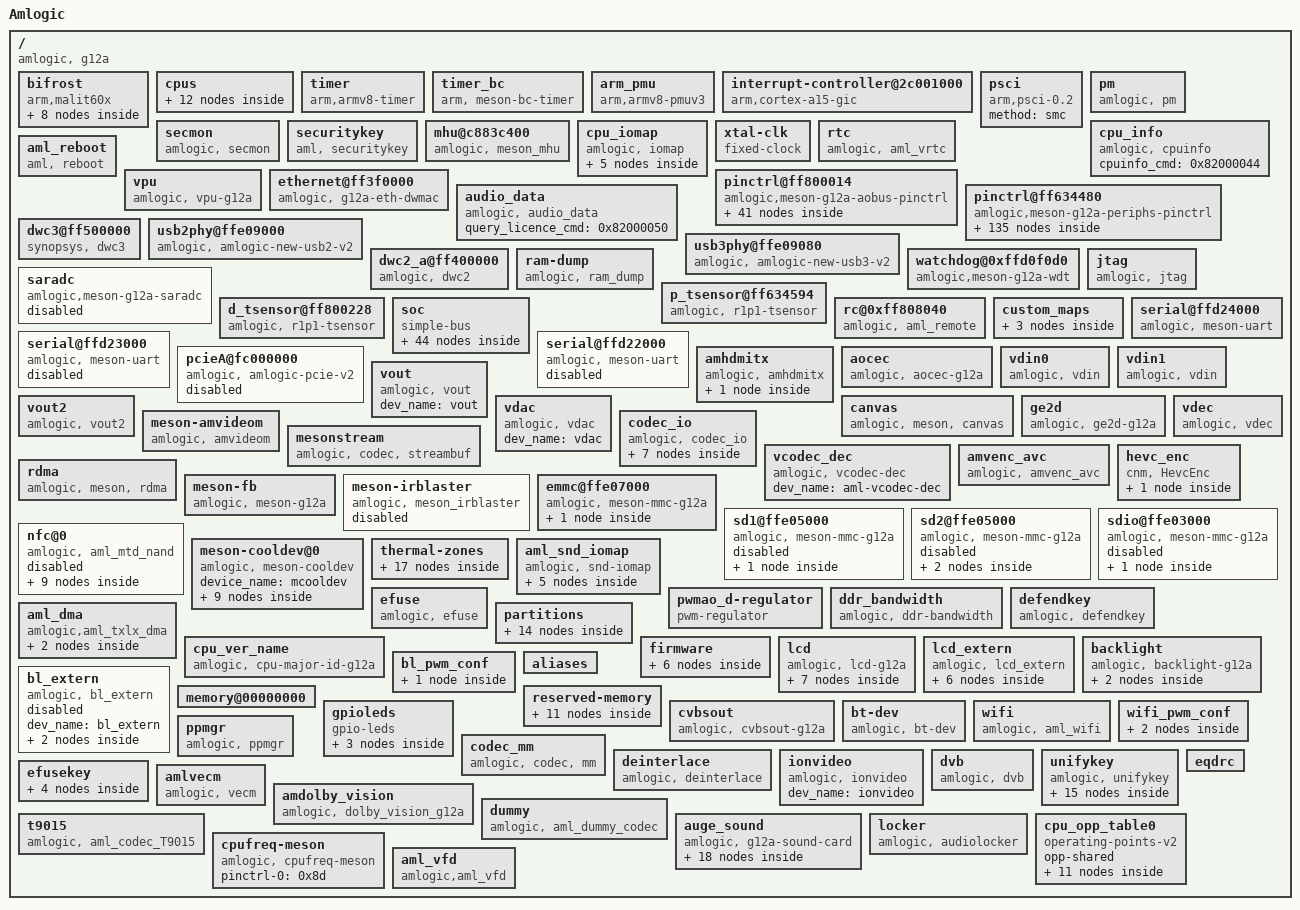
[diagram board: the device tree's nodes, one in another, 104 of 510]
/dts-v1/;

/ {
	model = "Amlogic";
	amlogic-dt-id = "g12a_x2_g10x2g";
	compatible = "amlogic, g12a";
	interrupt-parent = <0x1>;
	#address-cells = <0x2>;
	#size-cells = <0x2>;

	bifrost {
		compatible = "arm,malit60x", "arm,malit6xx", "arm,mali-midgard";
		#cooling-cells = <0x2>;
		reg = <0x0 0xffe40000 0x0 0x4000 0x0 0xffd01000 0x0 0x1000 0x0 0xff800000 0x0 0x1000 0x0 0xff63c000 0x0 0x1000 0x0 0xffd01000 0x0 0x1000>;
		interrupt-parent = <0x1>;
		interrupts = <0x0 0xa0 0x4 0x0 0xa1 0x4 0x0 0xa2 0x4>;
		interrupt-names = "GPU", "MMU", "JOB";
		num_of_pp = <0x2>;
		sc_mpp = <0x1>;
		clocks = <0x2 0x83 0x2 0x7>;
		clock-names = "gpu_mux", "gp0_pll";
		tbl = <0x3 0x4 0x5 0x6 0x7 0x7>;

		clk125_cfg {
			clk_freq = <0x7735940>;
			clk_parent = "fclk_div4";
			clkp_freq = <0x1dcd6500>;
			clk_reg = <0xa03>;
			voltage = <0x47e>;
			keep_count = <0x5>;
			threshold = <0x1e 0x78>;
		};

		dvfs250_cfg {
			clk_freq = <0xee6b280>;
			clk_parent = "fclk_div4";
			clkp_freq = <0x1dcd6500>;
			clk_reg = <0xa01>;
			voltage = <0x47e>;
			keep_count = <0x5>;
			threshold = <0x50 0xaa>;
		};

		dvfs285_cfg {
			clk_freq = <0x1107a76d>;
			clk_parent = "fclk_div7";
			clkp_freq = <0x1107a76d>;
			clk_reg = <0xe00>;
			voltage = <0x47e>;
			keep_count = <0x5>;
			threshold = <0x64 0xbe>;
			linux,phandle = <0x3>;
			phandle = <0x3>;
		};

		dvfs400_cfg {
			clk_freq = <0x17d78400>;
			clk_parent = "fclk_div5";
			clkp_freq = <0x17d78400>;
			clk_reg = <0xc00>;
			voltage = <0x47e>;
			keep_count = <0x5>;
			threshold = <0x98 0xcf>;
			linux,phandle = <0x4>;
			phandle = <0x4>;
		};

		dvfs500_cfg {
			clk_freq = <0x1dcd6500>;
			clk_parent = "fclk_div4";
			clkp_freq = <0x1dcd6500>;
			clk_reg = <0xa00>;
			voltage = <0x47e>;
			keep_count = <0x5>;
			threshold = <0xb4 0xdc>;
			linux,phandle = <0x5>;
			phandle = <0x5>;
		};

		dvfs666_cfg {
			clk_freq = <0x27bc86aa>;
			clk_parent = "fclk_div3";
			clkp_freq = <0x27bc86aa>;
			clk_reg = <0x800>;
			voltage = <0x47e>;
			keep_count = <0x5>;
			threshold = <0xd2 0xec>;
			linux,phandle = <0x6>;
			phandle = <0x6>;
		};

		dvfs800_cfg {
			clk_freq = <0x2faf0800>;
			clk_parent = "fclk_div2p5";
			clkp_freq = <0x2faf0800>;
			clk_reg = <0x600>;
			voltage = <0x47e>;
			keep_count = <0x5>;
			threshold = <0xe6 0xff>;
		};

		dvfs850_cfg {
			clk_freq = <0x326cef80>;
			clk_parent = "gp0_pll";
			clkp_freq = <0x326cef80>;
			clk_reg = <0x200>;
			voltage = <0x47e>;
			keep_count = <0x5>;
			threshold = <0xe6 0xff>;
			linux,phandle = <0x7>;
			phandle = <0x7>;
		};
	};

	cpus {
		#address-cells = <0x2>;
		#size-cells = <0x0>;

		cpu-map {

			cluster0 {

				core0 {
					cpu = <0x8>;
				};

				core1 {
					cpu = <0x9>;
				};

				core2 {
					cpu = <0xa>;
				};

				core3 {
					cpu = <0xb>;
				};
			};
		};

		cpu@0 {
			device_type = "cpu";
			compatible = "arm,cortex-a53", "arm,armv8";
			reg = <0x0 0x0>;
			enable-method = "psci";
			cpu-idle-states = <0xc>;
			clocks = <0x2 0x17 0x2 0x16 0x2 0x0>;
			clock-names = "core_clk", "low_freq_clk_parent", "high_freq_clk_parent";
			operating-points-v2 = <0xd>;
			cpu-supply = <0xe>;
			voltage-tolerance = <0x0>;
			clock-latency = <0xc350>;
			linux,phandle = <0x8>;
			phandle = <0x8>;
		};

		cpu@1 {
			device_type = "cpu";
			compatible = "arm,cortex-a53", "arm,armv8";
			reg = <0x0 0x1>;
			enable-method = "psci";
			cpu-idle-states = <0xc>;
			clocks = <0x2 0x17 0x2 0x16 0x2 0x0>;
			clock-names = "core_clk", "low_freq_clk_parent", "high_freq_clk_parent";
			operating-points-v2 = <0xd>;
			cpu-supply = <0xe>;
			voltage-tolerance = <0x0>;
			clock-latency = <0xc350>;
			linux,phandle = <0x9>;
			phandle = <0x9>;
		};

		cpu@2 {
			device_type = "cpu";
			compatible = "arm,cortex-a53", "arm,armv8";
			reg = <0x0 0x2>;
			enable-method = "psci";
			cpu-idle-states = <0xc>;
			clocks = <0x2 0x17 0x2 0x16 0x2 0x0>;
			clock-names = "core_clk", "low_freq_clk_parent", "high_freq_clk_parent";
			operating-points-v2 = <0xd>;
			cpu-supply = <0xe>;
			voltage-tolerance = <0x0>;
			clock-latency = <0xc350>;
			linux,phandle = <0xa>;
			phandle = <0xa>;
		};

		cpu@3 {
			device_type = "cpu";
			compatible = "arm,cortex-a53", "arm,armv8";
			reg = <0x0 0x3>;
			enable-method = "psci";
			cpu-idle-states = <0xc>;
			clocks = <0x2 0x17 0x2 0x16 0x2 0x0>;
			clock-names = "core_clk", "low_freq_clk_parent", "high_freq_clk_parent";
			operating-points-v2 = <0xd>;
			cpu-supply = <0xe>;
			voltage-tolerance = <0x0>;
			clock-latency = <0xc350>;
			linux,phandle = <0xb>;
			phandle = <0xb>;
		};

		idle-states {
			entry-method = "arm,psci-0.2";

			cpu-sleep-0 {
				compatible = "arm,idle-state";
				arm,psci-suspend-param = <0x10000>;
				local-timer-stop;
				entry-latency-us = <0x1388>;
				exit-latency-us = <0x1388>;
				min-residency-us = <0x3a98>;
				linux,phandle = <0xc>;
				phandle = <0xc>;
			};
		};
	};

	timer {
		compatible = "arm,armv8-timer";
		interrupts = <0x1 0xd 0xff08 0x1 0xe 0xff08 0x1 0xb 0xff08 0x1 0xa 0xff08>;
	};

	timer_bc {
		compatible = "arm, meson-bc-timer";
		reg = <0x0 0xffd0f190 0x0 0x4 0x0 0xffd0f194 0x0 0x4>;
		timer_name = "Meson TimerF";
		clockevent-rating = <0x12c>;
		clockevent-shift = <0x14>;
		clockevent-features = <0x23>;
		interrupts = <0x0 0x3c 0x1>;
		bit_enable = <0x10>;
		bit_mode = <0xc>;
		bit_resolution = <0x0>;
	};

	arm_pmu {
		compatible = "arm,armv8-pmuv3";
		interrupts = <0x0 0x89 0x4>;
		reg = <0x0 0xff634400 0x0 0x1000>;
		sys_cpu_status0_offset = <0xa0>;
		sys_cpu_status0_pmuirq_mask = <0xf>;
		relax_timer_ns = <0x989680>;
		max_wait_cnt = <0x2710>;
	};

	interrupt-controller@2c001000 {
		compatible = "arm,cortex-a15-gic", "arm,cortex-a9-gic";
		#interrupt-cells = <0x3>;
		#address-cells = <0x0>;
		interrupt-controller;
		reg = <0x0 0xffc01000 0x0 0x1000 0x0 0xffc02000 0x0 0x100>;
		interrupts = <0x1 0x9 0xf04>;
		linux,phandle = <0x1>;
		phandle = <0x1>;
	};

	psci {
		compatible = "arm,psci-0.2";
		method = "smc";
	};

	pm {
		compatible = "amlogic, pm";
		status = "okay";
		device_name = "aml_pm";
		reg = <0x0 0xff8000a8 0x0 0x4 0x0 0xff80023c 0x0 0x4>;
	};

	secmon {
		compatible = "amlogic, secmon";
		memory-region = <0xf>;
		in_base_func = <0x82000020>;
		out_base_func = <0x82000021>;
		reserve_mem_size = <0x300000>;
	};

	securitykey {
		compatible = "aml, securitykey";
		storage_query = <0x82000060>;
		storage_read = <0x82000061>;
		storage_write = <0x82000062>;
		storage_tell = <0x82000063>;
		storage_verify = <0x82000064>;
		storage_status = <0x82000065>;
		storage_list = <0x82000067>;
		storage_remove = <0x82000068>;
		storage_in_func = <0x82000023>;
		storage_out_func = <0x82000024>;
		storage_block_func = <0x82000025>;
		storage_size_func = <0x82000027>;
		storage_set_enctype = <0x8200006a>;
		storage_get_enctype = <0x8200006b>;
		storage_version = <0x8200006c>;
	};

	mhu@c883c400 {
		compatible = "amlogic, meson_mhu";
		reg = <0x0 0xff63c400 0x0 0x4c 0x0 0xfffe7000 0x0 0x800>;
		interrupts = <0x0 0xd1 0x1 0x0 0xd2 0x1>;
		#mbox-cells = <0x1>;
		mbox-names = "cpu_to_scp_low", "cpu_to_scp_high";
		mboxes = <0x10 0x0 0x10 0x1>;
		linux,phandle = <0x10>;
		phandle = <0x10>;
	};

	cpu_iomap {
		compatible = "amlogic, iomap";
		#address-cells = <0x2>;
		#size-cells = <0x2>;
		ranges;

		io_cbus_base {
			reg = <0x0 0xffd00000 0x0 0x26000>;
		};

		io_apb_base {
			reg = <0x0 0xffe01000 0x0 0x7f000>;
		};

		io_aobus_base {
			reg = <0x0 0xff800000 0x0 0xb000>;
		};

		io_vapb_base {
			reg = <0x0 0xff900000 0x0 0x50000>;
		};

		io_hiu_base {
			reg = <0x0 0xff63c000 0x0 0x2000>;
		};
	};

	xtal-clk {
		compatible = "fixed-clock";
		clock-frequency = <0x16e3600>;
		clock-output-names = "xtal";
		#clock-cells = <0x0>;
		linux,phandle = <0x14>;
		phandle = <0x14>;
	};

	rtc {
		compatible = "amlogic, aml_vrtc";
		alarm_reg_addr = <0xff8000a8>;
		timer_e_addr = <0xffd0f188>;
		init_date = "2015/01/01";
		status = "okay";
	};

	cpu_info {
		compatible = "amlogic, cpuinfo";
		status = "okay";
		cpuinfo_cmd = <0x82000044>;
	};

	aml_reboot {
		compatible = "aml, reboot";
		sys_reset = <0x84000009>;
		sys_poweroff = <0x84000008>;
	};

	vpu {
		compatible = "amlogic, vpu-g12a";
		dev_name = "vpu";
		status = "okay";
		clocks = <0x2 0x95 0x2 0x4c 0x2 0x87 0x2 0x8b 0x2 0x8c>;
		clock-names = "vapb_clk", "vpu_intr_gate", "vpu_clk0", "vpu_clk1", "vpu_clk";
		clk_level = <0x7>;
	};

	ethernet@ff3f0000 {
		compatible = "amlogic, g12a-eth-dwmac", "snps,dwmac";
		reg = <0x0 0xff3f0000 0x0 0x10000 0x0 0xff634540 0x0 0x8 0x0 0xff64c000 0x0 0xa0>;
		reg-names = "eth_base", "eth_cfg", "eth_pll";
		interrupts = <0x0 0x8 0x1>;
		interrupt-names = "macirq";
		status = "okay";
		clocks = <0x2 0x38>;
		clock-names = "ethclk81";
		pll_val = <0x9c0040a 0x927e0000 0xac5f49e5>;
		analog_val = <0x20200000 0xc000 0x23>;
		pinctrl-names = "external_eth_pins";
		pinctrl-0 = <0x11>;
		mc_val = <0x1621>;
		internal_phy = <0x0>;
	};

	pinctrl@ff800014 {
		compatible = "amlogic,meson-g12a-aobus-pinctrl";
		#address-cells = <0x2>;
		#size-cells = <0x2>;
		ranges;

		ao-bank@ff800014 {
			reg = <0x0 0xff800014 0x0 0x8 0x0 0xff800024 0x0 0x14 0x0 0xff80001c 0x0 0x8>;
			reg-names = "mux", "gpio", "drive-strength";
			gpio-controller;
			#gpio-cells = <0x2>;
			linux,phandle = <0x15>;
			phandle = <0x15>;
		};

		sd_to_ao_uart_clr_pins {
			linux,phandle = <0x40>;
			phandle = <0x40>;

			mux {
				groups = "GPIOAO_0", "GPIOAO_1";
				function = "gpio_aobus";
			};
		};

		sd_to_ao_uart_pins {
			linux,phandle = <0x42>;
			phandle = <0x42>;

			mux {
				groups = "uart_ao_tx_a", "uart_ao_rx_a";
				function = "uart_ao_a";
				bias-pull-up;
				input-enable;
			};
		};

		ao_uart {

			mux {
				groups = "uart_ao_tx_a", "uart_ao_rx_a";
				function = "uart_ao_a";
			};
		};

		ao_b_uart {
			linux,phandle = <0x1a>;
			phandle = <0x1a>;

			mux {
				groups = "uart_ao_tx_b_2", "uart_ao_rx_b_3";
				function = "uart_ao_b";
			};
		};

		ao_i2c_pins1 {

			mux {
				groups = "i2c_ao_sck", "i2c_ao_sda";
				function = "i2c_ao";
				drive-strength = <0x2>;
			};
		};

		ao_i2c_pins2 {

			mux {
				groups = "i2c_ao_sck_e", "i2c_ao_sda_e";
				function = "i2c_ao";
				drive-strength = <0x2>;
			};
		};

		ao_i2c_slave_pins {
			linux,phandle = <0x19>;
			phandle = <0x19>;

			mux {
				groups = "i2c_ao_slave_sck", "i2c_ao_slave_sda";
				function = "i2c_ao_slave";
			};
		};

		pwm_ao_a {

			mux {
				groups = "pwm_ao_a";
				function = "pwm_ao_a";
			};
		};

		pwm_ao_a_hiz {

			mux {
				groups = "pwm_ao_a_hiz";
				function = "pwm_ao_a";
			};
		};

		pwm_ao_b {

			mux {
				groups = "pwm_ao_b";
				function = "pwm_ao_b";
			};
		};

		pwm_ao_c_pins1 {

			mux {
				groups = "pwm_ao_c_4";
				function = "pwm_ao_c";
			};
		};

		pwm_ao_c_pins2 {

			mux {
				groups = "pwm_ao_c_6";
				function = "pwm_ao_c";
			};
		};

		pwm_ao_c_hiz {

			mux {
				groups = "pwm_ao_c_hiz_4";
				function = "pwm_ao_c";
			};
		};

		pwm_ao_d_pins1 {

			mux {
				groups = "pwm_ao_d_5";
				function = "pwm_ao_d";
			};
		};

		pwm_ao_d_pins2 {

			mux {
				groups = "pwm_ao_d_10";
				function = "pwm_ao_d";
			};
		};

		pwm_ao_d_pins3 {
			linux,phandle = <0x8d>;
			phandle = <0x8d>;

			mux {
				groups = "pwm_ao_d_e";
				function = "pwm_ao_d";
			};
		};

		ao_ceca {

			mux {
				groups = "cec_ao_a";
				function = "cec_ao";
			};
		};

		ao_cecb {

			mux {
				groups = "cec_ao_b";
				function = "cec_ao";
			};
		};

		remote_pin {
			linux,phandle = <0x27>;
			phandle = <0x27>;

			mux {
				groups = "remote_input_ao";
				function = "remote_input_ao";
			};
		};

		irblaster_pin {
			linux,phandle = <0x39>;
			phandle = <0x39>;

			mux {
				groups = "remote_out_ao";
				function = "remote_out_ao";
			};
		};
	};

	pinctrl@ff634480 {
		compatible = "amlogic,meson-g12a-periphs-pinctrl";
		#address-cells = <0x2>;
		#size-cells = <0x2>;
		ranges;

		banks@ff6346c0 {
			reg = <0x0 0xff6346c0 0x0 0x40 0x0 0xff6344e8 0x0 0x18 0x0 0xff634520 0x0 0x18 0x0 0xff634440 0x0 0x4c 0x0 0xff634740 0x0 0x1c>;
			reg-names = "mux", "pull", "pull-enable", "gpio", "drive-strength";
			gpio-controller;
			#gpio-cells = <0x2>;
			linux,phandle = <0x16>;
			phandle = <0x16>;
		};

		emmc_clk_cmd_pins {
			linux,phandle = <0x3a>;
			phandle = <0x3a>;

			mux {
				groups = "emmc_clk", "emmc_cmd";
				function = "emmc";
				input-enable;
				bias-pull-up;
			};
		};

		emmc_conf_pull_up {
			linux,phandle = <0x3b>;
			phandle = <0x3b>;

			mux {
				groups = "emmc_nand_d7", "emmc_nand_d6", "emmc_nand_d5", "emmc_nand_d4", "emmc_nand_d3", "emmc_nand_d2", "emmc_nand_d1", "emmc_nand_d0", "emmc_clk", "emmc_cmd";
				function = "emmc";
				input-enable;
				bias-pull-up;
			};
		};

		emmc_conf_pull_done {
			linux,phandle = <0x3c>;
			phandle = <0x3c>;

			mux {
				groups = "emmc_nand_ds";
				function = "emmc";
				input-enable;
				bias-pull-down;
			};
		};

		sd_clk_cmd_pins {
			linux,phandle = <0x3e>;
			phandle = <0x3e>;

			mux {
				groups = "sdcard_cmd_c";
				function = "sdcard";
				input-enable;
				bias-pull-up;
				drive-strength = <0x3>;
			};

			mux1 {
				groups = "sdcard_clk_c";
				function = "sdcard";
				bias-pull-up;
				output-high;
				drive-strength = <0x3>;
			};
		};

		sd_all_pins {
			linux,phandle = <0x3d>;
			phandle = <0x3d>;

			mux {
				groups = "sdcard_d0_c", "sdcard_d1_c", "sdcard_d2_c", "sdcard_d3_c", "sdcard_cmd_c";
				function = "sdcard";
				input-enable;
				bias-pull-up;
				drive-strength = <0x3>;
			};

			mux1 {
				groups = "sdcard_clk_c";
				function = "sdcard";
				bias-pull-up;
				output-high;
				drive-strength = <0x3>;
			};
		};

		sd_1bit_pins {
			linux,phandle = <0x3f>;
			phandle = <0x3f>;

			mux {
				groups = "sdcard_d0_c", "sdcard_cmd_c";
				function = "sdcard";
				input-enable;
				bias-pull-up;
				drive-strength = <0x3>;
			};

			mux1 {
				groups = "sdcard_clk_c";
				function = "sdcard";
				bias-pull-up;
				output-high;
				drive-strength = <0x3>;
			};
		};

		sd_clr_all_pins {
			linux,phandle = <0x46>;
			phandle = <0x46>;

			mux {
				groups = "GPIOC_0", "GPIOC_1", "GPIOC_2", "GPIOC_3", "GPIOC_5";
				function = "gpio_periphs";
				output-high;
				drive-strength = <0x0>;
			};

			mux1 {
				groups = "GPIOC_4";
				function = "gpio_periphs";
				output-low;
				drive-strength = <0x0>;
			};
		};

		sd_clr_noall_pins {
			linux,phandle = <0x45>;
			phandle = <0x45>;

			mux {
				groups = "GPIOC_0", "GPIOC_1", "GPIOC_4", "GPIOC_5";
				function = "gpio_periphs";
				output-high;
				drive-strength = <0x0>;
			};
		};

		ao_to_sd_uart_pins {
			linux,phandle = <0x41>;
			phandle = <0x41>;

			mux {
				groups = "uart_ao_tx_a_c3", "uart_ao_rx_a_c2";
				function = "uart_ao_a_ee";
				bias-pull-up;
				input-enable;
				drive-strength = <0x0>;
			};
		};

		sdio_clk_cmd_pins {
			linux,phandle = <0x4a>;
			phandle = <0x4a>;

			mux {
				groups = "sdio_clk", "sdio_cmd";
				function = "sdio";
				input-enable;
				bias-pull-up;
				drive-strength = <0x3>;
			};
		};

		sdio_all_pins {
			linux,phandle = <0x49>;
			phandle = <0x49>;

			mux {
				groups = "sdio_d0", "sdio_d1", "sdio_d2", "sdio_d3", "sdio_clk", "sdio_cmd";
				function = "sdio";
				input-enable;
				bias-pull-up;
				drive-strength = <0x3>;
			};
		};

		sdio_x_clk_cmd_pins {
			linux,phandle = <0x48>;
			phandle = <0x48>;

			mux {
				groups = "GPIOX_5";
				function = "gpio_periphs";
				input-enable;
				bias-pull-up;
				drive-strength = <0x3>;
			};

			mux1 {
				groups = "GPIOX_4";
				function = "gpio_periphs";
				bias-pull-up;
				output-high;
				drive-strength = <0x3>;
			};
		};

		sdio_x_all_pins {
			linux,phandle = <0x47>;
			phandle = <0x47>;

			mux {
				groups = "GPIOX_0", "GPIOX_1", "GPIOX_2", "GPIOX_3";
				function = "gpio_periphs";
				input-enable;
				bias-pull-up;
				drive-strength = <0x1>;
			};

			mux1 {
				groups = "GPIOX_5";
				function = "gpio_periphs";
				input-enable;
				bias-pull-up;
				drive-strength = <0x3>;
			};

			mux2 {
				groups = "GPIOX_4";
				function = "gpio_periphs";
				bias-pull-up;
				output-high;
				drive-strength = <0x3>;
			};
		};

		sdio_x_en_pins {
			linux,phandle = <0x44>;
			phandle = <0x44>;

			mux {
				groups = "sdio_dummy";
				function = "sdio";
				bias-pull-up;
				output-high;
			};
		};

		sdio_x_clr_pins {
			linux,phandle = <0x43>;
			phandle = <0x43>;

			mux {
				groups = "GPIOV_0";
				function = "gpio_periphs";
				bias-pull-up;
				output-low;
			};

			mux1 {
				groups = "GPIOX_4";
				function = "gpio_periphs";
				output-low;
			};
		};

		all_nand_pins {
			linux,phandle = <0x4b>;
			phandle = <0x4b>;

			mux {
				groups = "emmc_nand_d0", "emmc_nand_d1", "emmc_nand_d2", "emmc_nand_d3", "emmc_nand_d4", "emmc_nand_d5", "emmc_nand_d6", "emmc_nand_d7", "nand_ce0", "nand_ale", "nand_cle", "nand_wen_clk", "nand_ren_wr", "nand_rb0";
				function = "nand";
				input-enable;
			};
		};

		nand_cs {
			linux,phandle = <0x4c>;
			phandle = <0x4c>;

			mux {
				groups = "nand_ce0";
				function = "nand";
			};
		};

		i2c0_pins1 {

			mux {
				groups = "i2c0_sda_c", "i2c0_sck_c";
				function = "i2c0";
				drive-strength = <0x2>;
			};
		};

		i2c0_pins2 {
			linux,phandle = <0x17>;
			phandle = <0x17>;

			mux {
				groups = "i2c0_sda_z0", "i2c0_sck_z1";
				function = "i2c0";
				drive-strength = <0x2>;
			};
		};

		i2c0_pins3 {

			mux {
				groups = "i2c0_sda_z7", "i2c0_sck_z8";
				function = "i2c0";
				drive-strength = <0x2>;
			};
		};

		i2c1_pins1 {

			mux {
				groups = "i2c1_sda_x", "i2c1_sck_x";
				function = "i2c1";
				drive-strength = <0x2>;
			};
		};

		i2c1_pins2 {

			mux {
				groups = "i2c1_sda_h2", "i2c1_sck_h3";
				function = "i2c1";
				drive-strength = <0x2>;
			};
		};

		i2c1_pins3 {

			mux {
				groups = "i2c1_sda_h6", "i2c1_sck_h7";
				function = "i2c1";
				drive-strength = <0x2>;
			};
		};

		i2c2_pins1 {

			mux {
				groups = "i2c2_sda_x", "i2c2_sck_x";
				function = "i2c2";
				drive-strength = <0x2>;
			};
		};

		i2c2_pins2 {

			mux {
				groups = "i2c2_sda_z", "i2c2_sck_z";
				function = "i2c2";
				drive-strength = <0x2>;
			};
		};

		i2c3_pins1 {
			linux,phandle = <0x33>;
			phandle = <0x33>;

			mux {
				groups = "i2c3_sda_h", "i2c3_sck_h";
				function = "i2c3";
				drive-strength = <0x2>;
			};
		};

		i2c3_pins2 {
			linux,phandle = <0x18>;
			phandle = <0x18>;

			mux {
				groups = "i2c3_sda_a", "i2c3_sck_a";
				function = "i2c3";
				drive-strength = <0x2>;
			};
		};

		pwm_a {

			mux {
				groups = "pwm_a";
				function = "pwm_a";
			};
		};

		pwm_b_pins1 {

			mux {
				groups = "pwm_b_x7";
				function = "pwm_b";
			};
		};

		pwm_b_pins2 {

			mux {
				groups = "pwm_b_x19";
				function = "pwm_b";
			};
		};

		pwm_c_pins1 {

			mux {
				groups = "pwm_c_c4";
				function = "pwm_c";
			};
		};

		pwm_c_pins2 {

			mux {
				groups = "pwm_c_x5";
				function = "pwm_c";
			};
		};

		pwm_c_pins3 {

			mux {
				groups = "pwm_c_x8";
				function = "pwm_c";
			};
		};

		pwm_d_pins1 {

			mux {
				groups = "pwm_d_x3";
				function = "pwm_d";
			};
		};

		pwm_d_pins2 {

			mux {
				groups = "pwm_d_x6";
				function = "pwm_d";
			};
		};

		pwm_e {
			linux,phandle = <0x6a>;
			phandle = <0x6a>;

			mux {
				groups = "pwm_e";
				function = "pwm_e";
			};
		};

		pwm_f_pins1 {

			mux {
				groups = "pwm_f_x";
				function = "pwm_f";
			};
		};

		pwm_f_pins2 {
			linux,phandle = <0x67>;
			phandle = <0x67>;

			mux {
				groups = "pwm_f_h";
				function = "pwm_f";
			};
		};

		spicc0_pins_x {

			mux {
				groups = "spi0_mosi_x", "spi0_miso_x", "spi0_clk_x";
				function = "spi0";
				drive-strength = <0x1>;
			};
		};

		spicc0_pins_c {

			mux {
				groups = "spi0_mosi_c", "spi0_miso_c", "spi0_ss0_c", "spi0_clk_c";
				function = "spi0";
				drive-strength = <0x1>;
			};
		};

		spicc1_pins {

			mux {
				groups = "spi1_mosi", "spi1_miso", "spi1_clk";
				function = "spi1";
				drive-strength = <0x1>;
			};
		};

		a_uart {
			linux,phandle = <0x2c>;
			phandle = <0x2c>;

			mux {
				groups = "uart_tx_a", "uart_rx_a", "uart_cts_a", "uart_rts_a";
				function = "uart_a";
			};
		};

		b_uart {
			linux,phandle = <0x2d>;
			phandle = <0x2d>;

			mux {
				groups = "uart_tx_b", "uart_rx_b";
				function = "uart_b";
			};
		};

		c_uart {
			linux,phandle = <0x2e>;
			phandle = <0x2e>;

			mux {
				groups = "uart_tx_c", "uart_rx_c";
				function = "uart_c";
			};
		};

		hdmitx_hpd {
			linux,phandle = <0x30>;
			phandle = <0x30>;

			mux {
				groups = "hdmitx_hpd_in";
				function = "hdmitx";
				bias-disable;
			};
		};

		hdmitx_hpd_gpio {
			linux,phandle = <0x32>;
			phandle = <0x32>;

			mux {
				groups = "GPIOH_1";
				function = "gpio_periphs";
				bias-disable;
			};
		};

		hdmitx_ddc {
			linux,phandle = <0x31>;
			phandle = <0x31>;

			mux {
				groups = "hdmitx_sda", "hdmitx_sck";
				function = "hdmitx";
				bias-disable;
				drive-strength = <0x3>;
			};
		};

		ee_ceca {
			linux,phandle = <0x34>;
			phandle = <0x34>;

			mux {
				groups = "cec_ao_a_ee";
				function = "cec_ao_ee";
			};
		};

		ee_cecb {
			linux,phandle = <0x35>;
			phandle = <0x35>;

			mux {
				groups = "cec_ao_b_ee";
				function = "cec_ao_ee";
			};
		};

		internal_eth_pins {

			mux {
				groups = "eth_link_led", "eth_act_led";
				function = "eth";
			};
		};

		internal_gpio_pins {

			mux {
				groups = "GPIOZ_14", "GPIOZ_15";
				function = "gpio_periphs";
				bias-disable;
				input-enable;
			};
		};

		external_eth_pins {
			linux,phandle = <0x11>;
			phandle = <0x11>;

			mux {
				groups = "eth_mdio", "eth_mdc", "eth_rgmii_rx_clk", "eth_rx_dv", "eth_rxd0", "eth_rxd1", "eth_rxd2_rgmii", "eth_rxd3_rgmii", "eth_rgmii_tx_clk", "eth_txen", "eth_txd0", "eth_txd1", "eth_txd2_rgmii", "eth_txd3_rgmii";
				function = "eth";
				drive-strength = <0x3>;
			};
		};

		tdmout_a {
			linux,phandle = <0x1d>;
			phandle = <0x1d>;

			mux {
				groups = "tdma_sclk", "tdma_fs", "tdma_dout0";
				function = "tdma_out";
			};
		};

		tdmin_a {
			linux,phandle = <0x1e>;
			phandle = <0x1e>;

			mux {
				groups = "tdma_din1";
				function = "tdma_in";
			};
		};

		tdmb_mclk {
			linux,phandle = <0x1f>;
			phandle = <0x1f>;

			mux {
				groups = "mclk0_a";
				function = "mclk0";
				drive-strength = <0x2>;
			};
		};

		tdmout_b {
			linux,phandle = <0x20>;
			phandle = <0x20>;

			mux {
				groups = "tdmb_sclk", "tdmb_fs", "tdmb_dout0";
				function = "tdmb_out";
				drive-strength = <0x2>;
			};
		};

		tdmin_b {
			linux,phandle = <0x21>;
			phandle = <0x21>;

			mux {
				groups = "tdmb_din1";
				function = "tdmb_in";
				drive-strength = <0x2>;
			};
		};

		tdmc_mclk {
			linux,phandle = <0x22>;
			phandle = <0x22>;

			mux {
				groups = "mclk1_a";
				function = "mclk1";
			};
		};

		tdmout_c {
			linux,phandle = <0x23>;
			phandle = <0x23>;

			mux {
				groups = "tdmc_sclk_a", "tdmc_fs_a", "tdmc_dout0_a";
				function = "tdmc_out";
			};
		};

		tdmin_c {
			linux,phandle = <0x24>;
			phandle = <0x24>;

			mux {
				groups = "tdmc_din1_a";
				function = "tdmc_in";
			};
		};

		spdifin {

			mux {
				groups = "spdif_in_h";
				function = "spdif_in";
			};
		};

		spdifout {
			linux,phandle = <0x25>;
			phandle = <0x25>;

			mux {
				groups = "spdif_out_h";
				function = "spdif_out";
			};
		};

		pdmin {
			linux,phandle = <0x26>;
			phandle = <0x26>;

			mux {
				groups = "pdm_din0_a", "pdm_din2_a", "pdm_dclk_a";
				function = "pdm";
			};
		};
	};

	audio_data {
		compatible = "amlogic, audio_data";
		query_licence_cmd = <0x82000050>;
		status = "okay";
	};

	dwc3@ff500000 {
		compatible = "synopsys, dwc3";
		status = "okay";
		reg = <0x0 0xff500000 0x0 0x100000>;
		interrupts = <0x0 0x1e 0x4>;
		usb-phy = <0x12 0x13>;
		cpu-type = "gxl";
		clock-src = "usb3.0";
		clocks = <0x2 0x41>;
		clock-names = "dwc_general";
	};

	usb2phy@ffe09000 {
		compatible = "amlogic, amlogic-new-usb2-v2";
		status = "okay";
		reg = <0x0 0xffe09000 0x0 0x80 0x0 0xffd01008 0x0 0x100 0x0 0xff636000 0x0 0x2000 0x0 0xff63a000 0x0 0x2000>;
		pll-setting-1 = <0x9400414>;
		pll-setting-2 = <0x927e0000>;
		pll-setting-3 = <0xac5f49e5>;
		pll-setting-4 = <0xfe18>;
		pll-setting-5 = <0xfff>;
		pll-setting-6 = <0xc8000>;
		pll-setting-7 = <0xe0004>;
		pll-setting-8 = <0xe000c>;
		portnum = <0x2>;
		linux,phandle = <0x12>;
		phandle = <0x12>;
	};

	usb3phy@ffe09080 {
		compatible = "amlogic, amlogic-new-usb3-v2";
		status = "okay";
		reg = <0x0 0xffe09080 0x0 0x20>;
		phy-reg = <0xff646000>;
		phy-reg-size = <0x2000>;
		usb2-phy-reg = <0xffe09000>;
		usb2-phy-reg-size = <0x80>;
		interrupts = <0x0 0x10 0x4>;
		clocks = <0x2 0x18>;
		clock-names = "pcie_refpll";
		portnum = <0x1>;
		otg = <0x0>;
		linux,phandle = <0x13>;
		phandle = <0x13>;
	};

	dwc2_a@ff400000 {
		compatible = "amlogic, dwc2";
		status = "okay";
		device_name = "dwc2_a";
		reg = <0x0 0xff400000 0x0 0x40000>;
		interrupts = <0x0 0x1f 0x4>;
		pl-periph-id = <0x0>;
		clock-src = "usb0";
		port-id = <0x0>;
		port-type = <0x2>;
		port-speed = <0x0>;
		port-config = <0x0>;
		port-dma = <0x0>;
		port-id-mode = <0x0>;
		usb-fifo = <0x2d8>;
		cpu-type = "v2";
		phy-reg = <0xffe09000>;
		phy-reg-size = <0xa0>;
		phy-interface = <0x0>;
		clocks = <0x2 0x41 0x2 0x49>;
		clock-names = "usb_general", "usb1";
		controller-type = <0x3>;
	};

	watchdog@0xffd0f0d0 {
		compatible = "amlogic,meson-g12a-wdt";
		status = "okay";
		reg = <0x0 0xffd0f0d0 0x0 0x10>;
		clock-names = "xtal";
		clocks = <0x14>;
	};

	ram-dump {
		compatible = "amlogic, ram_dump";
		status = "okay";
	};

	jtag {
		compatible = "amlogic, jtag";
		status = "okay";
		select = "apao";
		jtagao-gpios = <0x15 0x6 0x0 0x15 0x7 0x0 0x15 0x8 0x0 0x15 0x9 0x0>;
		jtagee-gpios = <0x16 0x2a 0x0 0x16 0x2b 0x0 0x16 0x2e 0x0 0x16 0x2f 0x0>;
	};

	saradc {
		compatible = "amlogic,meson-g12a-saradc";
		status = "disabled";
		#io-channel-cells = <0x1>;
		clocks = <0x14 0x2 0xeb>;
		clock-names = "xtal", "saradc_clk";
		interrupts = <0x0 0xc8 0x1>;
		reg = <0x0 0xff809000 0x0 0x48>;
	};

	p_tsensor@ff634594 {
		compatible = "amlogic, r1p1-tsensor";
		device_name = "meson-pthermal";
		status = "okay";
		reg = <0x0 0xff634800 0x0 0x50 0x0 0xff800268 0x0 0x4>;
		cal_type = <0x1>;
		cal_a = <0x144>;
		cal_b = <0x1a8>;
		cal_c = <0xc57>;
		cal_d = <0x24c3>;
		rtemp = <0x1fbd0>;
		interrupts = <0x0 0x23 0x0>;
		clocks = <0x2 0xd2>;
		clock-names = "ts_comp";
		#thermal-sensor-cells = <0x1>;
		linux,phandle = <0x50>;
		phandle = <0x50>;
	};

	d_tsensor@ff800228 {
		compatible = "amlogic, r1p1-tsensor";
		device_name = "meson-dthermal";
		status = "okay";
		reg = <0x0 0xff634c00 0x0 0x50 0x0 0xff800230 0x0 0x4>;
		cal_type = <0x1>;
		cal_a = <0x144>;
		cal_b = <0x1a8>;
		cal_c = <0xc57>;
		cal_d = <0x24c3>;
		rtemp = <0x1fbd0>;
		interrupts = <0x0 0x24 0x0>;
		clocks = <0x2 0xd2>;
		clock-names = "ts_comp";
		#thermal-sensor-cells = <0x1>;
		linux,phandle = <0x56>;
		phandle = <0x56>;
	};

	soc {
		compatible = "simple-bus";
		#address-cells = <0x2>;
		#size-cells = <0x2>;
		ranges;

		cbus@ffd00000 {
			compatible = "simple-bus";
			reg = <0x0 0xffd00000 0x0 0x26000>;
			#address-cells = <0x2>;
			#size-cells = <0x2>;
			ranges = <0x0 0x0 0x0 0xffd00000 0x0 0x26000>;

			interrupt-controller@f080 {
				compatible = "amlogic,meson-gpio-intc", "amlogic,meson-g12a-gpio-intc";
				reg = <0x0 0xf080 0x0 0x10>;
				interrupt-controller;
				#interrupt-cells = <0x2>;
				amlogic,channel-interrupts = <0x40 0x41 0x42 0x43 0x44 0x45 0x46 0x47>;
				status = "okay";
			};

			meson_clk_msr {
				compatible = "amlogic, gxl_measure";
				reg = <0x0 0x18004 0x0 0x4 0x0 0x1800c 0x0 0x4>;
				ringctrl = <0xff6345fc>;
			};

			pwm@1b000 {
				compatible = "amlogic,g12a-ee-pwm";
				reg = <0x0 0x1b000 0x0 0x20>;
				#pwm-cells = <0x3>;
				clocks = <0x14 0x14 0x14 0x14>;
				clock-names = "clkin0", "clkin1", "clkin2", "clkin3";
				status = "disabled";
			};

			pwm@1a000 {
				compatible = "amlogic,g12a-ee-pwm";
				reg = <0x0 0x1a000 0x0 0x20>;
				#pwm-cells = <0x3>;
				clocks = <0x14 0x14 0x14 0x14>;
				clock-names = "clkin0", "clkin1", "clkin2", "clkin3";
				status = "disabled";
			};

			pwm@19000 {
				compatible = "amlogic,g12a-ee-pwm";
				reg = <0x0 0x19000 0x0 0x20>;
				#pwm-cells = <0x3>;
				clocks = <0x14 0x14 0x14 0x14>;
				clock-names = "clkin0", "clkin1", "clkin2", "clkin3";
				status = "okay";
				linux,phandle = <0x69>;
				phandle = <0x69>;
			};

			i2c@1f000 {
				compatible = "amlogic,meson-g12a-i2c";
				status = "okay";
				reg = <0x0 0x1f000 0x0 0x20>;
				interrupts = <0x0 0x15 0x1 0x0 0x5b 0x1>;
				#address-cells = <0x1>;
				#size-cells = <0x0>;
				clocks = <0x2 0x2a>;
				clock-names = "clk_i2c";
				pinctrl-names = "default";
				pinctrl-0 = <0x17>;
				clock-frequency = <0x61a80>;

				gt9xx@5d {
					compatible = "goodix,gt9xx";
					status = "disabled";
					reg = <0x5d>;
					reset-gpio = <0x16 0xa 0x0>;
					irq-gpio = <0x16 0x4 0x0>;
				};

				ftxx@38 {
					compatible = "focaltech,fts";
					status = "disabled";
					reg = <0x38>;
					reset-gpio = <0x16 0xa 0x0>;
					irq-gpio = <0x16 0x4 0x0>;
					x_max = <0x258>;
					y_max = <0x400>;
					max-touch-number = <0xa>;
				};
			};

			i2c@1e000 {
				compatible = "amlogic,meson-g12a-i2c";
				status = "disabled";
				reg = <0x0 0x1e000 0x0 0x20>;
				interrupts = <0x0 0xd6 0x1 0x0 0x5c 0x1>;
				#address-cells = <0x1>;
				#size-cells = <0x0>;
				clocks = <0x2 0x2a>;
				clock-names = "clk_i2c";
			};

			i2c@1d000 {
				compatible = "amlogic,meson-g12a-i2c";
				status = "disabled";
				reg = <0x0 0x1d000 0x0 0x20>;
				interrupts = <0x0 0xd7 0x1 0x0 0x5e 0x1>;
				#address-cells = <0x1>;
				#size-cells = <0x0>;
				clocks = <0x2 0x2a>;
				clock-names = "clk_i2c";
			};

			i2c@1c000 {
				compatible = "amlogic,meson-g12a-i2c";
				status = "okay";
				reg = <0x0 0x1c000 0x0 0x20>;
				interrupts = <0x0 0x27 0x1 0x0 0x5f 0x1>;
				#address-cells = <0x1>;
				#size-cells = <0x0>;
				clocks = <0x2 0x2a>;
				clock-names = "clk_i2c";
				pinctrl-names = "default";
				pinctrl-0 = <0x18>;
				clock-frequency = <0x186a0>;

				ad82584f_62@62 {
					compatible = "ESMT, ad82584f";
					#sound-dai-cells = <0x0>;
					reg = <0x31>;
					status = "disabled";
					reset_pin = <0x16 0x37 0x0>;
				};

				tas5707_36@36 {
					compatible = "ti,tas5707";
					#sound-dai-cells = <0x0>;
					reg = <0x1b>;
					status = "disabled";
					reset_pin = <0x16 0x37 0x0>;
				};

				bl_extern_i2c {
					compatible = "amlogic, bl_extern_i2c";
					status = "disabled";
					reg = <0x2c>;
					dev_name = "lp8556";
				};

				hym8563@51 {
					compatible = "haoyu,hym8563";
					reg = <0x51>;
					interrupts = <0xd 0x2>;
					#clock-cells = <0x0>;
					status = "okay";
				};
			};

			spi@13000 {
				compatible = "amlogic,meson-g12a-spicc";
				reg = <0x0 0x13000 0x0 0x44>;
				interrupts = <0x0 0x51 0x4>;
				clocks = <0x2 0x29 0x2 0xcd>;
				clock-names = "core", "comp";
				#address-cells = <0x1>;
				#size-cells = <0x0>;
				status = "disabled";
			};

			spi@15000 {
				compatible = "amlogic,meson-g12a-spicc";
				reg = <0x0 0x15000 0x0 0x44>;
				interrupts = <0x0 0x5a 0x4>;
				clocks = <0x2 0x2f 0x2 0xd1>;
				clock-names = "core", "comp";
				#address-cells = <0x1>;
				#size-cells = <0x0>;
				status = "disabled";
			};
		};

		aobus@ff800000 {
			compatible = "simple-bus";
			reg = <0x0 0xff800000 0x0 0xb000>;
			#address-cells = <0x2>;
			#size-cells = <0x2>;
			ranges = <0x0 0x0 0x0 0xff800000 0x0 0xb000>;

			cpu_version {
				reg = <0x0 0x220 0x0 0x4>;
			};

			clock-controller@0 {
				compatible = "amlogic,g12a-aoclkc";
				#clock-cells = <0x1>;
				reg = <0x0 0x0 0x0 0x320>;
			};

			pwm@7000 {
				compatible = "amlogic,g12a-ao-pwm";
				reg = <0x0 0x7000 0x0 0x20>;
				#pwm-cells = <0x3>;
				clocks = <0x14 0x14 0x14 0x14>;
				clock-names = "clkin0", "clkin1", "clkin2", "clkin3";
				status = "disabled";
			};

			pwm@2000 {
				compatible = "amlogic,g12a-ao-pwm";
				reg = <0x0 0x2000 0x0 0x20>;
				#pwm-cells = <0x3>;
				clocks = <0x14 0x14 0x14 0x14>;
				clock-names = "clkin0", "clkin1", "clkin2", "clkin3";
				status = "okay";
				linux,phandle = <0x57>;
				phandle = <0x57>;
			};

			i2c@5000 {
				compatible = "amlogic,meson-g12a-i2c";
				status = "disabled";
				reg = <0x0 0x5000 0x0 0x20>;
				interrupts = <0x0 0xc3 0x1 0x0 0xc9 0x1>;
				#address-cells = <0x1>;
				#size-cells = <0x0>;
				clocks = <0x2 0x2a>;
				clock-names = "clk_i2c";
			};

			i2c_slave@6000 {
				compatible = "amlogic, meson-i2c-slave";
				status = "disabled";
				reg = <0x0 0x6000 0x0 0x20>;
				interrupts = <0x0 0xc2 0x1>;
				pinctrl-names = "default";
				pinctrl-0 = <0x19>;
			};

			serial@3000 {
				compatible = "amlogic, meson-uart";
				reg = <0x0 0x3000 0x0 0x18>;
				interrupts = <0x0 0xc1 0x1>;
				status = "okay";
				clocks = <0x14>;
				clock-names = "clk_uart";
				xtal_tick_en = <0x2>;
				fifosize = <0x40>;
				pinctrl-names = "default";
				support-sysrq = <0x0>;
			};

			serial@4000 {
				compatible = "amlogic, meson-uart";
				reg = <0x0 0x4000 0x0 0x18>;
				interrupts = <0x0 0xc5 0x1>;
				status = "disabled";
				clocks = <0x14>;
				clock-names = "clk_uart";
				fifosize = <0x40>;
				pinctrl-names = "default";
				pinctrl-0 = <0x1a>;
			};
		};

		periphs@ff634400 {
			compatible = "simple-bus";
			reg = <0x0 0xff634400 0x0 0x400>;
			#address-cells = <0x2>;
			#size-cells = <0x2>;
			ranges = <0x0 0x0 0x0 0xff634400 0x0 0x400>;
		};

		hiubus@ff63c000 {
			compatible = "simple-bus";
			reg = <0x0 0xff63c000 0x0 0x2000>;
			#address-cells = <0x2>;
			#size-cells = <0x2>;
			ranges = <0x0 0x0 0x0 0xff63c000 0x0 0x2000>;

			clock-controller@0 {
				compatible = "amlogic,g12a-clkc";
				#clock-cells = <0x1>;
				reg = <0x0 0x0 0x0 0x320>;
				linux,phandle = <0x2>;
				phandle = <0x2>;
			};
		};

		ion_dev {
			compatible = "amlogic, ion_dev";
			memory-region = <0x1b>;
		};

		audiobus@0xff642000 {
			compatible = "amlogic, audio-controller", "simple-bus";
			reg = <0x0 0xff642000 0x0 0x2000>;
			#address-cells = <0x2>;
			#size-cells = <0x2>;
			ranges = <0x0 0x0 0x0 0xff642000 0x0 0x2000>;

			audio_clocks {
				compatible = "amlogic, g12a-audio-clocks";
				#clock-cells = <0x1>;
				reg = <0x0 0x0 0x0 0xb0>;
				linux,phandle = <0x1c>;
				phandle = <0x1c>;
			};

			ddr_manager {
				compatible = "amlogic, g12a-audio-ddr-manager";
				interrupts = <0x0 0x94 0x1 0x0 0x95 0x1 0x0 0x96 0x1 0x0 0x98 0x1 0x0 0x99 0x1 0x0 0x9a 0x1>;
				interrupt-names = "toddr_a", "toddr_b", "toddr_c", "frddr_a", "frddr_b", "frddr_c";
			};

			tdma {
				compatible = "amlogic, g12a-snd-tdma";
				#sound-dai-cells = <0x0>;
				dai-tdm-lane-slot-mask-in = <0x0 0x1>;
				dai-tdm-oe-lane-slot-mask-out = <0x1 0x0>;
				dai-tdm-clk-sel = <0x0>;
				clocks = <0x1c 0x17 0x2 0xc>;
				clock-names = "mclk", "clk_srcpll";
				pinctrl-names = "tdm_pins";
				pinctrl-0 = <0x1d 0x1e>;
				linux,phandle = <0x86>;
				phandle = <0x86>;
			};

			tdmb {
				compatible = "amlogic, g12a-snd-tdmb";
				#sound-dai-cells = <0x0>;
				dai-tdm-lane-slot-mask-in = <0x0 0x1 0x0 0x0>;
				dai-tdm-lane-slot-mask-out = <0x1 0x0 0x0 0x0>;
				dai-tdm-clk-sel = <0x1>;
				clocks = <0x1c 0x18 0x2 0xd 0x2 0xc>;
				clock-names = "mclk", "clk_srcpll", "samesource_sysclk";
				pinctrl-names = "tdm_pins";
				pinctrl-0 = <0x1f 0x20 0x21>;
				samesource_sel = <0x3>;
				linux,phandle = <0x88>;
				phandle = <0x88>;
			};

			tdmc {
				compatible = "amlogic, g12a-snd-tdmc";
				#sound-dai-cells = <0x0>;
				dai-tdm-lane-slot-mask-in = <0x0 0x1 0x0 0x0>;
				#dai-tdm-lane-slot-mask-out = <0x1 0x0 0x1 0x1>;
				#dai-tdm-lane-oe-slot-mask-in = <0x0 0x0 0x0 0x0>;
				dai-tdm-lane-oe-slot-mask-out = <0x1 0x0 0x0 0x0>;
				dai-tdm-clk-sel = <0x2>;
				clocks = <0x1c 0x19 0x2 0xe>;
				clock-names = "mclk", "clk_srcpll";
				pinctrl-names = "tdm_pins";
				pinctrl-0 = <0x22 0x23 0x24>;
				linux,phandle = <0x89>;
				phandle = <0x89>;
			};

			i2s2hdmi {
				compatible = "amlogic, g12a-snd-tdmc";
				#sound-dai-cells = <0x0>;
				dai-tdm-lane-slot-mask-out = <0x1 0x1 0x1 0x1>;
				dai-tdm-clk-sel = <0x2>;
				clocks = <0x1c 0x19 0x2 0xe>;
				clock-names = "mclk", "clk_srcpll";
				i2s2hdmi = <0x1>;
				status = "disabled";
			};

			spdif {
				compatible = "amlogic, g12a-snd-spdif-a";
				#sound-dai-cells = <0x0>;
				clocks = <0x2 0xc 0x2 0x4 0x1c 0x10 0x1c 0x11 0x1c 0x1d 0x1c 0x1e>;
				clock-names = "sysclk", "fixed_clk", "gate_spdifin", "gate_spdifout", "clk_spdifin", "clk_spdifout";
				interrupts = <0x0 0x97 0x1>;
				interrupt-names = "irq_spdifin";
				pinctrl-names = "spdif_pins";
				pinctrl-0 = <0x25>;
				status = "okay";
				linux,phandle = <0x8b>;
				phandle = <0x8b>;
			};

			spdif_b {
				compatible = "amlogic, g12a-snd-spdif-b";
				#sound-dai-cells = <0x0>;
				clocks = <0x2 0xc 0x1c 0x15 0x1c 0x21>;
				clock-names = "sysclk", "gate_spdifout", "clk_spdifout";
				status = "okay";
				linux,phandle = <0x8c>;
				phandle = <0x8c>;
			};

			pdm {
				compatible = "amlogic, g12a-snd-pdm";
				#sound-dai-cells = <0x0>;
				clocks = <0x1c 0x1 0x2 0x3 0x2 0xf 0x1c 0x1f 0x1c 0x20>;
				clock-names = "gate", "sysclk_srcpll", "dclk_srcpll", "pdm_dclk", "pdm_sysclk";
				pinctrl-names = "pdm_pins";
				pinctrl-0 = <0x26>;
				filter_mode = <0x1>;
				status = "okay";
				linux,phandle = <0x8a>;
				phandle = <0x8a>;
			};

			loopback {
				compatible = "amlogic, snd-loopback";
				lb_mode = <0x0>;
				datain_src = <0x4>;
				datain_chnum = <0x8>;
				datain_chmask = <0x3f>;
				datalb_src = <0x2>;
				datalb_chnum = <0x8>;
				datalb_chmask = <0x3>;
				status = "okay";
				linux,phandle = <0x83>;
				phandle = <0x83>;
			};

			resample {
				compatible = "amlogic, g12a-resample";
				clocks = <0x2 0xf 0x1c 0x1c 0x1c 0x24>;
				clock-names = "resample_pll", "resample_src", "resample_clk";
				resample_module = <0x4>;
				status = "okay";
			};

			pwrdet {
				compatible = "amlogic, g12a-power-detect";
				interrupts = <0x0 0x9b 0x1>;
				interrupt-names = "pwrdet_irq";
				pwrdet_src = <0x4>;
				hi_th = <0x70000>;
				lo_th = <0x16000>;
				status = "disabled";
			};
		};
	};

	rc@0xff808040 {
		compatible = "amlogic, aml_remote";
		dev_name = "meson-remote";
		reg = <0x0 0xff808040 0x0 0x44 0x0 0xff808000 0x0 0x20>;
		status = "okay";
		protocol = <0x1>;
		led_blink = <0x1>;
		led_blink_frq = <0x64>;
		interrupts = <0x0 0xc4 0x1>;
		pinctrl-names = "default";
		pinctrl-0 = <0x27>;
		map = <0x28>;
		max_frame_time = <0xc8>;
	};

	custom_maps {
		mapnum = <0x3>;
		map0 = <0x29>;
		map1 = <0x2a>;
		map2 = <0x2b>;
		linux,phandle = <0x28>;
		phandle = <0x28>;

		map_0 {
			mapname = "amlogic-remote-1";
			customcode = <0xfb04>;
			release_delay = <0x50>;
			size = <0x32>;
			keymap = <0x47000b 0x130002 0x100003 0x110004 0xf0005 0xc0006 0xd0007 0xb0008 0x80009 0x9000a 0x5c0061 0x51003d 0x50003e 0x40003f 0x4d0040 0x430041 0x170042 0x43 0x10044 0x160057 0x49000e 0x60082 0x140083 0x440067 0x1d006c 0x1c0069 0x48006a 0x53007d 0x450068 0x19006d 0x520077 0x5007a 0x59007b 0x1b0078 0x40079 0x1a0074 0xa000f 0xe0071 0x1f0066 0x1e0084 0x70085 0x120086 0x540087 0x20088 0x4f001e 0x420030 0x5d002e 0x4c0020 0x580089 0x55008c>;
			linux,phandle = <0x29>;
			phandle = <0x29>;
		};

		map_1 {
			mapname = "amlogic-remote-2";
			customcode = <0xfe01>;
			release_delay = <0x50>;
			size = <0x35>;
			keymap = <0x10002 0x20003 0x30004 0x40005 0x50006 0x60007 0x70008 0x80009 0x9000a 0xa000b 0x1f01d2 0x15008b 0x16000f 0xc0192 0xd0193 0xe0073 0xf0072 0x110066 0x1c006a 0x1b0069 0x190067 0x1a006c 0x1d001c 0x170071 0x4900db 0x43009e 0x1201d5 0x1401d6 0x1801d7 0x590166 0x5a00a6 0x100074 0x4200a5 0x4400a3 0x1e00a8 0x4b00d0 0x5800a4 0x460082 0x400083 0x380046 0x5701d0 0x5b01d1 0x54018e 0x4c018f 0x4e0190 0x550191 0x5300ed 0x5200ee 0x3900d4 0x4100d5 0xb00d6 0xd8 0x1300d9>;
			linux,phandle = <0x2a>;
			phandle = <0x2a>;
		};

		map_2 {
			mapname = "amlogic-remote-3";
			customcode = <0xbd02>;
			release_delay = <0x50>;
			size = <0x11>;
			keymap = <0xca0067 0xd2006c 0x990069 0xc1006a 0xce0061 0x450074 0xc50085 0x800071 0xd0000f 0xd6007d 0x950066 0xdd0068 0x8c006d 0x890083 0x9c0082 0x9a0078 0xcd0079>;
			linux,phandle = <0x2b>;
			phandle = <0x2b>;
		};
	};

	serial@ffd24000 {
		compatible = "amlogic, meson-uart";
		reg = <0x0 0xffd24000 0x0 0x18>;
		interrupts = <0x0 0x1a 0x1>;
		status = "okay";
		clocks = <0x14 0x2 0x2e>;
		clock-names = "clk_uart", "clk_gate";
		fifosize = <0x80>;
		pinctrl-names = "default";
		pinctrl-0 = <0x2c>;
	};

	serial@ffd23000 {
		compatible = "amlogic, meson-uart";
		reg = <0x0 0xffd23000 0x0 0x18>;
		interrupts = <0x0 0x4b 0x1>;
		status = "disabled";
		clocks = <0x14 0x2 0x3c>;
		clock-names = "clk_uart", "clk_gate";
		fifosize = <0x40>;
		pinctrl-names = "default";
		pinctrl-0 = <0x2d>;
	};

	serial@ffd22000 {
		compatible = "amlogic, meson-uart";
		reg = <0x0 0xffd22000 0x0 0x18>;
		interrupts = <0x0 0x5d 0x1>;
		status = "disabled";
		clocks = <0x14 0x2 0x3c>;
		clock-names = "clk_uart", "clk_gate";
		fifosize = <0x40>;
		pinctrl-names = "default";
		pinctrl-0 = <0x2e>;
	};

	pcieA@fc000000 {
		compatible = "amlogic, amlogic-pcie-v2", "snps,dw-pcie";
		reg = <0x0 0xfc000000 0x0 0x400000 0x0 0xff648000 0x0 0x2000 0x0 0xfc400000 0x0 0x200000 0x0 0xff646000 0x0 0x2000 0x0 0xffd01080 0x0 0x10>;
		reg-names = "elbi", "cfg", "config", "phy", "reset";
		interrupts = <0x0 0xdd 0x0>;
		#interrupt-cells = <0x1>;
		bus-range = <0x0 0xff>;
		#address-cells = <0x3>;
		#size-cells = <0x2>;
		interrupt-map-mask = <0x0 0x0 0x0 0x0>;
		interrupt-map = <0x0 0x0 0x0 0x0 0x1 0x0 0xdf 0x1>;
		device_type = "pci";
		ranges = <0x81000000 0x0 0x0 0x0 0xfc600000 0x0 0x100000 0x82000000 0x0 0xfc700000 0x0 0xfc700000 0x0 0x1900000>;
		num-lanes = <0x1>;
		pcie-num = <0x1>;
		clocks = <0x2 0x18 0x2 0x3f 0x2 0x42>;
		clock-names = "pcie_refpll", "pcie", "pcie_phy";
		gpio-type = <0x2>;
		pcie-apb-rst-bit = <0xf>;
		pcie-phy-rst-bit = <0xe>;
		pcie-ctrl-a-rst-bit = <0xc>;
		status = "disable";
		reset-gpio = <0x16 0x49 0x0>;
	};

	amhdmitx {
		compatible = "amlogic, amhdmitx";
		dev_name = "amhdmitx";
		status = "okay";
		vend-data = <0x2f>;
		pinctrl-names = "default", "hdmitx_i2c";
		pinctrl-0 = <0x30 0x31>;
		pinctrl-1 = <0x32 0x33>;
		clocks = <0x2 0x55 0x2 0x4e 0x2 0x4f 0x2 0x95 0x2 0x8c>;
		clock-names = "venci_top_gate", "venci_0_gate", "venci_1_gate", "hdmi_vapb_clk", "hdmi_vpu_clk";
		interrupts = <0x0 0x39 0x1>;
		interrupt-names = "hdmitx_hpd";
		ic_type = <0xa>;

		vend_data {
			vendor_name = "Amlogic";
			vendor_id = <0x0>;
			linux,phandle = <0x2f>;
			phandle = <0x2f>;
		};
	};

	aocec {
		compatible = "amlogic, aocec-g12a";
		device_name = "aocec";
		status = "okay";
		vendor_name = "Amlogic";
		vendor_id = <0x0>;
		product_desc = "G12A";
		cec_osd_string = "AML_MBOX";
		cec_version = <0x5>;
		port_num = <0x1>;
		ee_cec;
		arc_port_mask = <0x2>;
		interrupts = <0x0 0xcb 0x1 0x0 0xc7 0x1>;
		interrupt-names = "hdmi_aocecb", "hdmi_aocec";
		pinctrl-names = "default", "hdmitx_aocecb", "cec_pin_sleep";
		pinctrl-0 = <0x34>;
		pinctrl-1 = <0x35>;
		pinctrl-2 = <0x35>;
		reg = <0x0 0xff80023c 0x0 0x4 0x0 0xff800000 0x0 0x400 0x0 0xff634400 0x0 0x26>;
		reg-names = "ao_exit", "ao", "periphs";
	};

	vdin0 {
		compatible = "amlogic, vdin";
		dev_name = "vdin0";
		status = "okay";
		reserve-iomap = "true";
		flag_cma = <0x0>;
		interrupts = <0x0 0x53 0x1>;
		rdma-irq = <0x2>;
		vdin_id = <0x0>;
		memory-region = <0x36>;
		tv_bit_mode = <0x15>;
	};

	vdin1 {
		compatible = "amlogic, vdin";
		dev_name = "vdin1";
		status = "okay";
		reserve-iomap = "true";
		flag_cma = <0x0>;
		interrupts = <0x0 0x55 0x1>;
		rdma-irq = <0x4>;
		vdin_id = <0x1>;
		memory-region = <0x37>;
		tv_bit_mode = <0x1>;
	};

	vout {
		compatible = "amlogic, vout";
		dev_name = "vout";
		status = "okay";
	};

	vout2 {
		compatible = "amlogic, vout2";
		dev_name = "vout";
		status = "okay";
		clocks = <0x2 0xc4 0x2 0xc9>;
		clock-names = "vpu_clkc0", "vpu_clkc";
	};

	vdac {
		compatible = "amlogic, vdac";
		dev_name = "vdac";
		status = "okay";
	};

	canvas {
		compatible = "amlogic, meson, canvas";
		dev_name = "amlogic-canvas";
		status = "okay";
		reg = <0x0 0xff638000 0x0 0x2000>;
	};

	ge2d {
		compatible = "amlogic, ge2d-g12a";
		dev_name = "ge2d";
		status = "okay";
		interrupts = <0x0 0x92 0x1>;
		interrupt-names = "ge2d";
		clocks = <0x2 0x95 0x2 0x3d 0x2 0x96>;
		clock-names = "clk_vapb_0", "clk_ge2d", "clk_ge2d_gate";
		reg = <0x0 0xff940000 0x0 0x10000>;
	};

	meson-amvideom {
		compatible = "amlogic, amvideom";
		dev_name = "amvideom";
		status = "okay";
		interrupts = <0x0 0x3 0x1>;
		interrupt-names = "vsync";
	};

	codec_io {
		compatible = "amlogic, codec_io";
		status = "okay";
		#address-cells = <0x2>;
		#size-cells = <0x2>;
		ranges;

		io_cbus_base {
			reg = <0x0 0xffd00000 0x0 0x100000>;
		};

		io_dos_base {
			reg = <0x0 0xff620000 0x0 0x10000>;
		};

		io_hiubus_base {
			reg = <0x0 0xff63c000 0x0 0x2000>;
		};

		io_aobus_base {
			reg = <0x0 0xff800000 0x0 0x10000>;
		};

		io_vcbus_base {
			reg = <0x0 0xff900000 0x0 0x40000>;
		};

		io_dmc_base {
			reg = <0x0 0xff638000 0x0 0x2000>;
		};

		io_efuse_base {
			reg = <0x0 0xff630000 0x0 0x2000>;
		};
	};

	mesonstream {
		compatible = "amlogic, codec, streambuf";
		dev_name = "mesonstream";
		status = "okay";
		clocks = <0x2 0x40 0x2 0x39 0x2 0x43 0x2 0x22 0x2 0xa5 0x2 0xae 0x2 0xb7 0x2 0xc0>;
		clock-names = "parser_top", "demux", "ahbarb0", "vdec", "clk_vdec_mux", "clk_hcodec_mux", "clk_hevc_mux", "clk_hevcb_mux";
	};

	vdec {
		compatible = "amlogic, vdec";
		dev_name = "vdec.0";
		status = "okay";
		interrupts = <0x0 0x3 0x1 0x0 0x17 0x1 0x0 0x20 0x1 0x0 0x2b 0x1 0x0 0x2c 0x1 0x0 0x2d 0x1>;
		interrupt-names = "vsync", "demux", "parser", "mailbox_0", "mailbox_1", "mailbox_2";
	};

	vcodec_dec {
		compatible = "amlogic, vcodec-dec";
		dev_name = "aml-vcodec-dec";
		status = "okay";
	};

	amvenc_avc {
		compatible = "amlogic, amvenc_avc";
		dev_name = "amvenc_avc";
		status = "okay";
		interrupts = <0x0 0x2d 0x1>;
		interrupt-names = "mailbox_2";
	};

	hevc_enc {
		compatible = "cnm, HevcEnc";
		dev_name = "HevcEnc";
		status = "okay";
		interrupts = <0x0 0xbb 0x1>;
		interrupt-names = "wave420l_irq";
		#address-cells = <0x2>;
		#size-cells = <0x2>;
		ranges;

		io_reg_base {
			reg = <0x0 0xff610000 0x0 0x4000>;
		};
	};

	rdma {
		compatible = "amlogic, meson, rdma";
		dev_name = "amlogic-rdma";
		status = "okay";
		interrupts = <0x0 0x59 0x1>;
		interrupt-names = "rdma";
	};

        meson-fb {
                compatible = "amlogic, meson-g12a";
                memory-region = <&fb_reserved>;
                dev_name = "meson-fb";
                status = "okay";
                interrupts = <0 3 1
                        0 89 1>;
                interrupt-names = "viu-vsync", "rdma";
                mem_size = <0x00800000 0x1800000 0x00100000>;
                /* uboot logo,fb0/fb1 memory size,if afbcd fb0=0x01851000 */
                display_mode_default = "1080p60hz";
                scale_mode = <1>;
                /** 0:VPU free scale 1:OSD free scale 2:OSD super scale */
                display_size_default = <1920 1080 1920 3240 32>;
                /*1920*1080*4*3 = 0x17BB000*/
                mem_alloc = <1>;
                logo_addr = "0x7dc00000";
        };

	meson-irblaster {
		compatible = "amlogic, meson_irblaster";
		dev_name = "meson-irblaster";
		reg = <0x0 0xff80014c 0x0 0x10 0x0 0xff800040 0x0 0x4>;
		pinctrl-names = "default";
		pinctrl-0 = <0x39>;
		status = "disable";
	};

	emmc@ffe07000 {
		status = "okay";
		compatible = "amlogic, meson-mmc-g12a";
		reg = <0x0 0xffe07000 0x0 0x800>;
		interrupts = <0x0 0xbf 0x1>;
		pinctrl-names = "emmc_clk_cmd_pins", "emmc_all_pins";
		pinctrl-0 = <0x3a>;
		pinctrl-1 = <0x3b 0x3c>;
		clocks = <0x2 0x35 0x2 0x72 0x2 0x2 0x2 0x5 0x14>;
		clock-names = "core", "clkin0", "clkin1", "clkin2", "xtal";
		bus-width = <0x8>;
		cap-sd-highspeed;
		cap-mmc-highspeed;
		max-frequency = <0xbebc200>;
		non-removable;
		disable-wp;

		emmc {
			pinname = "emmc";
			ocr_avail = <0x200080>;
			tx_delay = <0x0>;
			co_phase = <0x3>;
			calc_f = <0x1>;
			max_req_size = <0x20000>;
			gpio_dat3 = <0x16 0x1d 0x0>;
			hw_reset = <0x16 0x23 0x0>;
			card_type = <0x1>;
			caps = "MMC_CAP_8_BIT_DATA", "MMC_CAP_MMC_HIGHSPEED", "MMC_CAP_SD_HIGHSPEED", "MMC_CAP_NONREMOVABLE", "MMC_CAP_HW_RESET", "MMC_CAP_ERASE", "MMC_CAP_CMD23";
			caps2 = "MMC_CAP2_HS200";
			f_min = <0x61a80>;
			f_max = <0xbebc200>;
		};
	};

	sd1@ffe05000 {
		status = "disabled";
		compatible = "amlogic, meson-mmc-g12a";
		reg = <0x0 0xffe05000 0x0 0x800>;
		interrupts = <0x0 0xbe 0x1>;
		pinctrl-names = "sd_all_pins", "sd_clk_cmd_pins", "sd_1bit_pins", "sd_clk_cmd_uart_pins", "sd_1bit_uart_pins", "sd_to_ao_uart_pins", "ao_to_sd_uart_pins", "sd_to_ao_jtag_pins", "ao_to_sd_jtag_pins";
		pinctrl-0 = <0x3d>;
		pinctrl-1 = <0x3e>;
		pinctrl-2 = <0x3f>;
		pinctrl-3 = <0x40 0x3e 0x41>;
		pinctrl-4 = <0x40 0x3f 0x41>;
		pinctrl-5 = <0x3d 0x42>;
		pinctrl-6 = <0x40 0x41>;
		pinctrl-7 = <0x3d 0x42>;
		pinctrl-8 = <0x40 0x41>;
		clocks = <0x2 0x34 0x2 0x6e 0x2 0x2 0x2 0x5 0x14>;
		clock-names = "core", "clkin0", "clkin1", "clkin2", "xtal";
		bus-width = <0x4>;
		cap-sd-highspeed;
		cap-mmc-highspeed;
		max-frequency = <0x5f5e100>;
		disable-wp;

		sd {
			pinname = "sd";
			ocr_avail = <0x200080>;
			max_req_size = <0x20000>;
			gpio_dat3 = <0x16 0x2d 0x0>;
			jtag_pin = <0x16 0x2a 0x0>;
			gpio_cd = <0x16 0x30 0x0>;
			card_type = <0x5>;
			caps = "MMC_CAP_4_BIT_DATA", "MMC_CAP_MMC_HIGHSPEED", "MMC_CAP_SD_HIGHSPEED";
			f_min = <0x61a80>;
			f_max = <0x2faf080>;
		};
	};

	sd2@ffe05000 {
		status = "disabled";
		compatible = "amlogic, meson-mmc-g12a";
		reg = <0x0 0xffe05000 0x0 0x800>;
		interrupts = <0x0 0xbe 0x4>;
		pinctrl-names = "sd_all_pins", "sd_clk_cmd_pins", "sd_1bit_pins", "sd_clk_cmd_uart_pins", "sd_1bit_uart_pins", "sd_to_ao_uart_pins", "ao_to_sd_uart_pins", "sd_to_ao_jtag_pins", "ao_to_sd_jtag_pins", "sdio_noclr_all_pins", "sdio_noclr_clk_cmd_pins", "sdio_all_pins", "sdio_clk_cmd_pins";
		pinctrl-0 = <0x43 0x3d>;
		pinctrl-1 = <0x43 0x3e>;
		pinctrl-2 = <0x43 0x3f>;
		pinctrl-3 = <0x43 0x40 0x3e 0x41>;
		pinctrl-4 = <0x43 0x40 0x3f 0x41>;
		pinctrl-5 = <0x43 0x3d 0x42>;
		pinctrl-6 = <0x44 0x40 0x45 0x41>;
		pinctrl-7 = <0x44 0x46 0x42>;
		pinctrl-8 = <0x44 0x40 0x45 0x41>;
		pinctrl-9 = <0x45 0x44 0x47>;
		pinctrl-10 = <0x45 0x44 0x48>;
		pinctrl-11 = <0x46 0x44 0x47>;
		pinctrl-12 = <0x46 0x44 0x48>;
		clocks = <0x2 0x34 0x2 0x6e 0x2 0x2 0x2 0x5 0x14>;
		clock-names = "core", "clkin0", "clkin1", "clkin2", "xtal";
		bus-width = <0x4>;
		cap-sd-highspeed;
		cap-mmc-highspeed;
		max-frequency = <0x5f5e100>;
		disable-wp;

		sd {
			pinname = "sd";
			ocr_avail = <0x200080>;
			max_req_size = <0x20000>;
			gpio_dat3 = <0x16 0x2d 0x0>;
			jtag_pin = <0x16 0x2a 0x0>;
			gpio_cd = <0x16 0x30 0x0>;
			card_type = <0x5>;
			caps = "MMC_CAP_4_BIT_DATA", "MMC_CAP_MMC_HIGHSPEED", "MMC_CAP_SD_HIGHSPEED";
			f_min = <0x61a80>;
			f_max = <0x2faf080>;
		};

		sdio {
			pinname = "sdio";
			ocr_avail = <0x200080>;
			max_req_size = <0x20000>;
			card_type = <0x3>;
			caps = "MMC_CAP_4_BIT_DATA", "MMC_CAP_MMC_HIGHSPEED", "MMC_CAP_SD_HIGHSPEED", "MMC_CAP_NONREMOVABLE", "MMC_CAP_UHS_SDR12", "MMC_CAP_UHS_SDR25", "MMC_CAP_UHS_SDR50", "MMC_CAP_UHS_SDR104", "MMC_PM_KEEP_POWER", "MMC_CAP_SDIO_IRQ";
			f_min = <0x61a80>;
			f_max = <0xbebc200>;
		};
	};

	sdio@ffe03000 {
		status = "disabled";
		compatible = "amlogic, meson-mmc-g12a";
		reg = <0x0 0xffe03000 0x0 0x800>;
		interrupts = <0x0 0xbd 0x4>;
		pinctrl-names = "sdio_all_pins", "sdio_clk_cmd_pins";
		pinctrl-0 = <0x49>;
		pinctrl-1 = <0x4a>;
		clocks = <0x2 0x33 0x2 0x6a 0x2 0x2 0x2 0x5 0x14>;
		clock-names = "core", "clkin0", "clkin1", "clkin2", "xtal";
		bus-width = <0x4>;
		cap-sd-highspeed;
		cap-mmc-highspeed;
		max-frequency = <0x5f5e100>;
		disable-wp;

		sdio {
			pinname = "sdio";
			ocr_avail = <0x200080>;
			max_req_size = <0x400>;
			card_type = <0x3>;
			dmode = "pio";
			caps = "MMC_CAP_4_BIT_DATA", "MMC_CAP_MMC_HIGHSPEED", "MMC_CAP_SD_HIGHSPEED", "MMC_CAP_NONREMOVABLE", "MMC_CAP_UHS_SDR12", "MMC_CAP_UHS_SDR25", "MMC_CAP_UHS_SDR50", "MMC_CAP_UHS_SDR104", "MMC_PM_KEEP_POWER", "MMC_CAP_SDIO_IRQ";
			f_min = <0x61a80>;
			f_max = <0xbebc200>;
		};
	};

	nfc@0 {
		compatible = "amlogic, aml_mtd_nand";
		dev_name = "mtdnand";
		status = "disabled";
		reg = <0x0 0xffe07800 0x0 0x200>;
		interrupts = <0x0 0x22 0x1>;
		pinctrl-names = "nand_rb_mod", "nand_norb_mod", "nand_cs_only";
		pinctrl-0 = <0x4b>;
		pinctrl-1 = <0x4b>;
		pinctrl-2 = <0x4c>;
		clocks = <0x2 0x35 0x2 0x72>;
		clock-names = "core", "clkin";
		device_id = <0x0>;
		bl_mode = <0x1>;
		fip_copies = <0x4>;
		fip_size = <0x200000>;
		nand_clk_ctrl = <0xffe07000>;
		plat-names = "bootloader", "nandnormal";
		plat-num = <0x2>;
		plat-part-0 = <0x4d>;
		plat-part-1 = <0x4e>;

		bootloader {
			enable_pad = "ce0";
			busy_pad = "rb0";
			timming_mode = "mode5";
			bch_mode = "bch8_1k";
			t_rea = <0x14>;
			t_rhoh = <0xf>;
			chip_num = <0x1>;
			part_num = <0x0>;
			rb_detect = <0x1>;
			linux,phandle = <0x4d>;
			phandle = <0x4d>;
		};

		nandnormal {
			enable_pad = "ce0";
			busy_pad = "rb0";
			timming_mode = "mode5";
			bch_mode = "bch8_1k";
			plane_mode = "twoplane";
			t_rea = <0x14>;
			t_rhoh = <0xf>;
			chip_num = <0x2>;
			part_num = <0x3>;
			partition = <0x4f>;
			rb_detect = <0x1>;
			linux,phandle = <0x4e>;
			phandle = <0x4e>;
		};

		nand_partition {
			linux,phandle = <0x4f>;
			phandle = <0x4f>;

			tpl {
				offset = <0x0 0x0>;
				size = <0x0 0x0>;
			};

			logo {
				offset = <0x0 0x0>;
				size = <0x0 0x200000>;
			};

			recovery {
				offset = <0x0 0x0>;
				size = <0x0 0x1000000>;
			};

			boot {
				offset = <0x0 0x0>;
				size = <0x0 0x1000000>;
			};

			system {
				offset = <0x0 0x0>;
				size = <0x0 0x4000000>;
			};

			data {
				offset = <0xffffffff 0xffffffff>;
				size = <0x0 0x0>;
			};
		};
	};

	meson-cooldev@0 {
		status = "okay";
		compatible = "amlogic, meson-cooldev";
		device_name = "mcooldev";

		cooling_devices {

			cpufreq_cool_cluster0 {
				min_state = <0xf4240>;
				dyn_coeff = <0x73>;
				cluster_id = <0x0>;
				node_name = "cpufreq_cool0";
				device_type = "cpufreq";
			};

			cpucore_cool_cluster0 {
				min_state = <0x1>;
				dyn_coeff = <0x0>;
				cluster_id = <0x0>;
				node_name = "cpucore_cool0";
				device_type = "cpucore";
			};

			gpufreq_cool {
				min_state = <0x190>;
				dyn_coeff = <0x166>;
				gpu_pp = <0x2>;
				cluster_id = <0x0>;
				node_name = "gpufreq_cool0";
				device_type = "gpufreq";
			};

			gpucore_cool {
				min_state = <0x1>;
				dyn_coeff = <0x0>;
				cluster_id = <0x0>;
				node_name = "gpucore_cool0";
				device_type = "gpucore";
			};
		};

		cpufreq_cool0 {
			#cooling-cells = <0x2>;
			linux,phandle = <0x52>;
			phandle = <0x52>;
		};

		cpucore_cool0 {
			#cooling-cells = <0x2>;
			linux,phandle = <0x53>;
			phandle = <0x53>;
		};

		gpufreq_cool0 {
			#cooling-cells = <0x2>;
			linux,phandle = <0x54>;
			phandle = <0x54>;
		};

		gpucore_cool0 {
			#cooling-cells = <0x2>;
			linux,phandle = <0x55>;
			phandle = <0x55>;
		};
	};

	thermal-zones {

		soc_thermal {
			polling-delay = <0x3e8>;
			polling-delay-passive = <0x64>;
			sustainable-power = <0x5b4>;
			thermal-sensors = <0x50 0x0>;

			trips {

				trip-point@0 {
					temperature = <0xea60>;
					hysteresis = <0x1388>;
					type = "passive";
				};

				trip-point@1 {
					temperature = <0x124f8>;
					hysteresis = <0x1388>;
					type = "passive";
					linux,phandle = <0x51>;
					phandle = <0x51>;
				};

				trip-point@2 {
					temperature = <0x14c08>;
					hysteresis = <0x1388>;
					type = "hot";
				};

				trip-point@3 {
					temperature = <0x249f0>;
					hysteresis = <0x3e8>;
					type = "critical";
				};
			};

			cooling-maps {

				cpufreq_cooling_map {
					trip = <0x51>;
					cooling-device = <0x52 0x0 0x4>;
					contribution = <0x400>;
				};

				cpucore_cooling_map {
					trip = <0x51>;
					cooling-device = <0x53 0x0 0x3>;
					contribution = <0x400>;
				};

				gpufreq_cooling_map {
					trip = <0x51>;
					cooling-device = <0x54 0x0 0x4>;
					contribution = <0x400>;
				};

				gpucore_cooling_map {
					trip = <0x51>;
					cooling-device = <0x55 0x0 0x2>;
					contribution = <0x400>;
				};
			};
		};

		ddr_thermal {
			polling-delay = <0x3e8>;
			polling-delay-passive = <0x64>;
			sustainable-power = <0x866>;
			thermal-sensors = <0x56 0x1>;

			trips {

				trip-point@0 {
					temperature = <0xea60>;
					hysteresis = <0x1388>;
					type = "passive";
				};

				trip-point@1 {
					temperature = <0x124f8>;
					hysteresis = <0x1388>;
					type = "passive";
				};

				trip-point@2 {
					temperature = <0x14c08>;
					hysteresis = <0x1388>;
					type = "hot";
				};

				trip-point@3 {
					temperature = <0x249f0>;
					hysteresis = <0x3e8>;
					type = "critical";
				};
			};
		};
	};

	aml_snd_iomap {
		compatible = "amlogic, snd-iomap";
		status = "okay";
		#address-cells = <0x2>;
		#size-cells = <0x2>;
		ranges;

		pdm_bus {
			reg = <0x0 0xff640000 0x0 0x2000>;
		};

		audiobus_base {
			reg = <0x0 0xff642000 0x0 0x2000>;
		};

		audiolocker_base {
			reg = <0x0 0xff64a000 0x0 0x2000>;
		};

		eqdrc_base {
			reg = <0x0 0xff642800 0x0 0x1800>;
		};

		reset_base {
			reg = <0x0 0xffd01000 0x0 0x1000>;
		};
	};

	pwmao_d-regulator {
		compatible = "pwm-regulator";
		pwms = <0x57 0x1 0x4e2 0x0>;
		regulator-name = "vddcpu0";
		regulator-min-microvolt = <0xb0068>;
		regulator-max-microvolt = <0xf9830>;
		regulator-always-on;
		max-duty-cycle = <0x4e2>;
		voltage-table = <0xf9830 0x0 0xf6d38 0x3 0xf4628 0x6 0xf1f18 0xa 0xef808 0xd 0xed0f8 0x10 0xea9e8 0x14 0xe82d8 0x17 0xe5bc8 0x1a 0xe34b8 0x1e 0xe0da8 0x21 0xde698 0x24 0xdbf88 0x28 0xd9878 0x2b 0xd7168 0x2e 0xd4a58 0x32 0xd2348 0x35 0xcfc38 0x38 0xcd528 0x3c 0xcae18 0x3f 0xc8708 0x43 0xc5ff8 0x46 0xc38e8 0x49 0xc11d8 0x4c 0xbeac8 0x50 0xbc3b8 0x53 0xb9ca8 0x56 0xb7598 0x5a 0xb4e88 0x5d 0xb2778 0x60 0xb0068 0x64>;
		status = "okay";
		linux,phandle = <0xe>;
		phandle = <0xe>;
	};

	ddr_bandwidth {
		compatible = "amlogic, ddr-bandwidth";
		status = "okay";
		reg = <0x0 0xff638000 0x0 0x100 0x0 0xff638c00 0x0 0x100>;
		interrupts = <0x0 0x34 0x1>;
		interrupt-names = "ddr_bandwidth";
	};

	defendkey {
		compatible = "amlogic, defendkey";
		reg = <0x0 0xff630218 0x0 0x4>;
		mem_size = <0x0 0x1000>;
		status = "okay";
	};

	aml_dma {
		compatible = "amlogic,aml_txlx_dma";
		reg = <0x0 0xff63e000 0x0 0x48>;
		interrupts = <0x0 0xb4 0x1>;

		aml_aes {
			compatible = "amlogic,aes_g12a_dma";
			dev_name = "aml_aes_dma";
			status = "okay";
		};

		aml_sha {
			compatible = "amlogic,sha_dma";
			dev_name = "aml_sha_dma";
			status = "okay";
		};
	};

	efuse {
		compatible = "amlogic, efuse";
		read_cmd = <0x82000030>;
		write_cmd = <0x82000031>;
		get_max_cmd = <0x82000033>;
		key = <0x58>;
		clocks = <0x2 0x61>;
		clock-names = "efuse_clk";
		status = "okay";
	};

	cpu_ver_name {
		compatible = "amlogic, cpu-major-id-g12a";
	};

	partitions {
		parts = <0xe>;
		part-0 = <0x59>;
		part-1 = <0x5a>;
		part-2 = <0x5b>;
		part-3 = <0x5c>;
		part-4 = <0x5d>;
		part-5 = <0x5e>;
		part-6 = <0x5f>;
		part-7 = <0x60>;
		part-8 = <0x61>;
		part-9 = <0x62>;
		part-10 = <0x63>;
		part-11 = <0x64>;
		part-12 = <0x65>;
		part-13 = <0x66>;

		logo {
			pname = "logo";
			size = <0x0 0x800000>;
			mask = <0x1>;
			linux,phandle = <0x59>;
			phandle = <0x59>;
		};

		recovery {
			pname = "recovery";
			size = <0x0 0x1800000>;
			mask = <0x1>;
			linux,phandle = <0x5a>;
			phandle = <0x5a>;
		};

		misc {
			pname = "misc";
			size = <0x0 0x800000>;
			mask = <0x1>;
			linux,phandle = <0x5b>;
			phandle = <0x5b>;
		};

		dto {
			pname = "dto";
			size = <0x0 0x800000>;
			mask = <0x1>;
			linux,phandle = <0x5c>;
			phandle = <0x5c>;
		};

		cri_data {
			pname = "cri_data";
			size = <0x0 0x800000>;
			mask = <0x2>;
			linux,phandle = <0x5d>;
			phandle = <0x5d>;
		};

		rsv {
			pname = "rsv";
			size = <0x0 0x1000000>;
			mask = <0x1>;
			linux,phandle = <0x60>;
			phandle = <0x60>;
		};

		param {
			pname = "param";
			size = <0x0 0x1000000>;
			mask = <0x2>;
			linux,phandle = <0x5e>;
			phandle = <0x5e>;
		};

		boot {
			pname = "boot";
			size = <0x0 0x1000000>;
			mask = <0x1>;
			linux,phandle = <0x5f>;
			phandle = <0x5f>;
		};

		tee {
			pname = "tee";
			size = <0x0 0x2000000>;
			mask = <0x1>;
			linux,phandle = <0x61>;
			phandle = <0x61>;
		};

		vendor {
			pname = "vendor";
			size = <0x0 0x10000000>;
			mask = <0x1>;
			linux,phandle = <0x62>;
			phandle = <0x62>;
		};

		odm {
			pname = "odm";
			size = <0x0 0x10000000>;
			mask = <0x1>;
			linux,phandle = <0x63>;
			phandle = <0x63>;
		};

		system {
			pname = "system";
			size = <0x0 0x74000000>;
			mask = <0x1>;
			linux,phandle = <0x64>;
			phandle = <0x64>;
		};

		cache {
			pname = "cache";
			size = <0x0 0x46000000>;
			mask = <0x2>;
			linux,phandle = <0x65>;
			phandle = <0x65>;
		};

		data {
			pname = "data";
			size = <0xffffffff 0xffffffff>;
			mask = <0x4>;
			linux,phandle = <0x66>;
			phandle = <0x66>;
		};
	};

	firmware {

		android {
			compatible = "android,firmware";

			vbmeta {
				compatible = "android,vbmeta";
				parts = "boot,system,vendor";
				by_name_prefix = "/dev/block";
			};

			fstab {
				compatible = "android,fstab";

				system {
					compatible = "android,system";
					dev = "/dev/block/system";
					type = "ext4";
					mnt_flags = "ro,barrier=1,inode_readahead_blks=8";
					fsmgr_flags = "wait";
				};

				vendor {
					compatible = "android,vendor";
					dev = "/dev/block/vendor";
					type = "ext4";
					mnt_flags = "ro,barrier=1,inode_readahead_blks=8";
					fsmgr_flags = "wait";
				};

				odm {
					compatible = "android,odm";
					dev = "/dev/block/odm";
					type = "ext4";
					mnt_flags = "ro,barrier=1,inode_readahead_blks=8";
					fsmgr_flags = "wait";
				};
			};
		};
	};

	lcd {
		compatible = "amlogic, lcd-g12a";
		dev_name = "lcd";
		mode = "tablet";
		status = "okay";
		key_valid = <0x0>;
		clocks = <0x2 0x24 0x2 0x31 0x2 0x9a 0x2 0x5d 0x2 0x5f>;
		clock-names = "dsi_host_gate", "dsi_phy_gate", "dsi_meas", "encl_top_gate", "encl_int_gate";
		reg = <0x0 0xffd07000 0x0 0x400 0x0 0xff644000 0x0 0x2000>;
		pinctrl_version = <0x2>;
		lcd_cpu-gpios = <0x16 0xa 0x0 0x16 0x9 0x0>;
		lcd_cpu_gpio_names = "GPIOZ_9", "GPIOZ_8";

		lcd_0 {
			model_name = "B080XAN01";
			interface = "mipi";
			basic_setting = <0x300 0x400 0x3b4 0x474 0x8 0x77 0x9f>;
			lcd_timing = <0x40 0x38 0x0 0x32 0x1e 0x0>;
			clk_attr = <0x0 0x0 0x1 0x3dd6dc0>;
			mipi_attr = <0x4 0x226 0x0 0x1 0x0 0x2 0x1 0x0>;
			dsi_init_on = <0x5 0x1 0x11 0xff 0x14 0x5 0x1 0x29 0xff 0x14 0xff 0xff>;
			dsi_init_off = <0x5 0x1 0x28 0xff 0xa 0x5 0x1 0x10 0xff 0xa 0xff 0xff>;
			extern_init = <0xff>;
			power_on_step = <0x0 0x1 0x0 0x64 0x0 0x0 0x0 0xa 0x0 0x0 0x1 0x14 0x2 0x0 0x0 0x0 0xff 0x0 0x0 0x0>;
			power_off_step = <0x2 0x0 0x0 0x32 0x0 0x0 0x0 0xa 0x0 0x1 0x1 0x64 0xff 0x0 0x0 0x0>;
			backlight_index = <0x0>;
		};

		lcd_1 {
			model_name = "TV070WSM";
			interface = "mipi";
			basic_setting = <0x258 0x400 0x2bc 0x41d 0x8 0x5f 0xa3>;
			lcd_timing = <0x18 0x24 0x0 0x2 0x8 0x0>;
			clk_attr = <0x0 0x0 0x1 0x2a33390>;
			mipi_attr = <0x4 0x168 0x0 0x1 0x0 0x2 0x0 0x0>;
			dsi_init_on = <0xff 0xa 0xf0 0x3 0x0 0x1 0x1e 0xf0 0x3 0x0 0x0 0xa 0xf0 0x3 0x0 0x1 0x1e 0xfc 0x2 0x4 0x3 0xff 0xff>;
			dsi_init_off = <0xff 0xff>;
			extern_init = <0x1>;
			power_on_step = <0x0 0x1 0x0 0xc8 0x2 0x0 0x0 0x0 0xff 0x0 0x0 0x0>;
			power_off_step = <0x2 0x0 0x0 0x0 0x0 0x0 0x0 0x14 0x0 0x1 0x1 0x64 0xff 0x0 0x0 0x0>;
			backlight_index = <0x0>;
		};

		lcd_2 {
			model_name = "P070ACB";
			interface = "mipi";
			basic_setting = <0x258 0x400 0x2a8 0x4aa 0x8 0x3 0x5>;
			lcd_timing = <0x18 0x24 0x0 0xa 0x50 0x0>;
			clk_attr = <0x0 0x0 0x1 0x2e755c0>;
			mipi_attr = <0x4 0x190 0x0 0x1 0x0 0x2 0x0 0x0>;
			dsi_init_on = <0xff 0xa 0xf0 0x3 0x0 0x1 0x1e 0xf0 0x3 0x0 0x0 0xa 0xf0 0x3 0x0 0x1 0x1e 0xfc 0x2 0x4 0x3 0xff 0xff>;
			dsi_init_off = <0xff 0xff>;
			extern_init = <0x2>;
			power_on_step = <0x0 0x1 0x0 0xc8 0x2 0x0 0x0 0x0 0xff 0x0 0x0 0x0>;
			power_off_step = <0x2 0x0 0x0 0x0 0x0 0x0 0x0 0x14 0x0 0x1 0x1 0x64 0xff 0x0 0x0 0x0>;
			backlight_index = <0x0>;
		};

		lcd_3 {
			model_name = "TL050FHV02CT";
			interface = "mipi";
			basic_setting = <0x438 0x780 0x465 0x834 0x8 0x41 0x77>;
			lcd_timing = <0x5 0x1e 0x0 0x2c 0x6c 0x0>;
			clk_attr = <0x0 0x0 0x1 0x70a71c8>;
			mipi_attr = <0x4 0x3c0 0x0 0x1 0x0 0x2 0x1 0x0>;
			dsi_init_on = <0xff 0xff>;
			dsi_init_off = <0xff 0xff>;
			extern_init = <0x3>;
			power_on_step = <0x0 0x1 0x0 0xc8 0x0 0x0 0x1 0x14 0x0 0x0 0x0 0xa 0x0 0x0 0x1 0x14 0x2 0x0 0x0 0x0 0xff 0x0 0x0 0x0>;
			power_off_step = <0x2 0x0 0x0 0x0 0x0 0x0 0x0 0x14 0x0 0x1 0x1 0x64 0xff 0x0 0x0 0x0>;
			backlight_index = <0x0>;
		};

		lcd_4 {
			model_name = "TL070WSH27";
			interface = "mipi";
			basic_setting = <0x400 0x258 0x4e2 0x276 0x8 0x9a 0x56>;
			lcd_timing = <0x50 0x64 0x0 0x5 0x14 0x0>;
			clk_attr = <0x0 0x0 0x1 0x2d0fa50>;
			mipi_attr = <0x4 0x12c 0x0 0x1 0x0 0x2 0x1 0x0>;
			dsi_init_on = <0x5 0x1 0x11 0xff 0x14 0x5 0x1 0x29 0xff 0x14 0xff 0xff>;
			dsi_init_off = <0x5 0x1 0x28 0xff 0xa 0x5 0x1 0x10 0xff 0xa 0xff 0xff>;
			extern_init = <0xff>;
			power_on_step = <0x0 0x1 0x0 0x64 0x0 0x0 0x0 0xa 0x0 0x0 0x1 0x14 0x2 0x0 0x0 0x0 0xff 0x0 0x0 0x0>;
			power_off_step = <0x2 0x0 0x0 0x32 0x0 0x0 0x0 0xa 0x0 0x1 0x1 0x64 0xff 0x0 0x0 0x0>;
			backlight_index = <0x0>;
		};

		lcd_5 {
			model_name = "TV070WSM_FT";
			interface = "mipi";
			basic_setting = <0x258 0x400 0x2bc 0x41d 0x8 0x5f 0xa3>;
			lcd_timing = <0x18 0x24 0x0 0x2 0x8 0x0>;
			clk_attr = <0x0 0x0 0x1 0x2a33390>;
			mipi_attr = <0x4 0x168 0x0 0x1 0x0 0x2 0x0 0x0>;
			dsi_init_on = <0xff 0xa 0xf0 0x3 0x0 0x1 0x1e 0xf0 0x3 0x0 0x0 0xa 0xf0 0x3 0x0 0x1 0x1e 0xfc 0x2 0x4 0x3 0xff 0xff>;
			dsi_init_off = <0xff 0xff>;
			extern_init = <0x4>;
			power_on_step = <0x0 0x1 0x0 0xc8 0x2 0x0 0x0 0x0 0xff 0x0 0x0 0x0>;
			power_off_step = <0x2 0x0 0x0 0x0 0x0 0x0 0x0 0x14 0x0 0x1 0x1 0x64 0xff 0x0 0x0 0x0>;
			backlight_index = <0x0>;
		};

		lcd_6 {
			model_name = "P070ACB_FT";
			interface = "mipi";
			basic_setting = <0x258 0x400 0x302 0x42e 0x8 0x3 0x5>;
			lcd_timing = <0xa 0x50 0x0 0x6 0x14 0x0>;
			clk_attr = <0x0 0x0 0x1 0x2f24d90>;
			mipi_attr = <0x4 0x190 0x0 0x1 0x0 0x2 0x0 0x0>;
			dsi_init_on = <0xff 0xa 0xf0 0x3 0x0 0x1 0x1e 0xf0 0x3 0x0 0x0 0xa 0xf0 0x3 0x0 0x1 0x1e 0xfc 0x2 0x4 0x3 0xff 0xff>;
			dsi_init_off = <0xff 0xff>;
			extern_init = <0x5>;
			power_on_step = <0x0 0x1 0x0 0xc8 0x2 0x0 0x0 0x0 0xff 0x0 0x0 0x0>;
			power_off_step = <0x2 0x0 0x0 0x0 0x0 0x0 0x0 0x14 0x0 0x1 0x1 0x64 0xff 0x0 0x0 0x0>;
			backlight_index = <0x0>;
		};
	};

	lcd_extern {
		compatible = "amlogic, lcd_extern";
		dev_name = "lcd_extern";
		status = "okay";
		key_valid = <0x0>;

		extern_0 {
			index = <0x0>;
			extern_name = "mipi_default";
			status = "okay";
			type = <0x2>;
			cmd_size = <0xff>;
			init_on = <0xff 0xa 0x5 0x1 0x11 0xff 0x78 0x5 0x1 0x29 0xff 0xff>;
			init_off = <0x5 0x1 0x28 0xff 0xa 0x5 0x1 0x10 0xff 0x96 0xff 0xff>;
		};

		extern_1 {
			index = <0x1>;
			extern_name = "mipi_default";
			status = "okay";
			type = <0x2>;
			cmd_size = <0xff>;
			init_on = <0xff 0xa 0x15 0x2 0x62 0x1 0x39 0x5 0xff 0xaa 0x55 0x25 0x1 0x15 0x2 0xfc 0x8 0xff 0x1 0x15 0x2 0xfc 0x0 0x39 0x5 0xff 0xaa 0x55 0x25 0x0 0xff 0x14 0x39 0x6 0xf0 0x55 0xaa 0x52 0x8 0x0 0x39 0x3 0xb1 0x68 0x41 0x15 0x2 0xb5 0x88 0x15 0x2 0xb6 0xf 0x39 0x5 0xb8 0x1 0x1 0x12 0x1 0x39 0x3 0xbb 0x11 0x11 0x39 0x3 0xbc 0x5 0x5 0x15 0x2 0xc7 0x3 0x39 0x6 0xbd 0x3 0x2 0x19 0x17 0x0 0x15 0x2 0xc8 0x80 0x39 0x6 0xf0 0x55 0xaa 0x52 0x8 0x1 0x39 0x3 0xb2 0x1 0x1 0x39 0x3 0xb3 0x28 0x28 0x39 0x3 0xb4 0x14 0x14 0x39 0x3 0xb8 0x5 0x5 0x39 0x3 0xb9 0x45 0x45 0x39 0x3 0xba 0x25 0x25 0x39 0x3 0xbc 0x88 0x0 0x39 0x3 0xbd 0x88 0x0 0x39 0x6 0xf0 0x55 0xaa 0x52 0x8 0x2 0x15 0x2 0xee 0x0 0x39 0x11 0xb0 0x0 0x4b 0x0 0x5c 0x0 0x79 0x0 0x94 0x0 0xa6 0x0 0xd8 0x0 0xf2 0x1 0x19 0x39 0x11 0xb1 0x1 0x39 0x1 0x77 0x1 0xa2 0x1 0xf2 0x2 0x32 0x2 0x34 0x2 0x6d 0x2 0xa2 0x39 0x11 0xb2 0x2 0xc7 0x2 0xf2 0x3 0x18 0x3 0x43 0x3 0x65 0x3 0x86 0x3 0x8f 0x3 0x94 0x39 0x5 0xb3 0x3 0x96 0x3 0x98 0x39 0x11 0xb4 0x0 0x84 0x0 0x91 0x0 0xa4 0x0 0xb6 0x0 0xca 0x0 0xe9 0x1 0x2 0x1 0x2a 0x39 0x11 0xb5 0x1 0x49 0x1 0x82 0x1 0xaf 0x1 0xf7 0x2 0x36 0x2 0x38 0x2 0x70 0x2 0xa6 0x39 0x11 0xb6 0x2 0xc8 0x2 0xf5 0x3 0x1a 0x3 0x43 0x3 0x62 0x3 0x82 0x3 0x8f 0x3 0x94 0x39 0x5 0xb7 0x3 0x96 0x3 0x98 0x39 0x11 0xb8 0x1 0x22 0x1 0x27 0x1 0x2e 0x1 0x38 0x1 0x40 0x1 0x53 0x1 0x60 0x1 0x7b 0x39 0x11 0xb9 0x1 0x8c 0x1 0xb5 0x1 0xd3 0x2 0x11 0x2 0x49 0x2 0x4a 0x2 0x7f 0x2 0xb1 0x39 0x11 0xba 0x2 0xd1 0x3 0x0 0x3 0x22 0x3 0x49 0x3 0x60 0x3 0x7a 0x3 0x8b 0x3 0x8f 0x39 0x5 0xbb 0x3 0x93 0x3 0x9a 0x39 0x11 0xbc 0x0 0x37 0x0 0x48 0x0 0x65 0x0 0x80 0x0 0x92 0x0 0xc4 0x0 0xde 0x1 0x5 0x39 0x11 0xbd 0x1 0x31 0x1 0x6f 0x1 0x9e 0x1 0xee 0x2 0x32 0x2 0x34 0x2 0x71 0x2 0xa7 0x39 0x11 0xbe 0x2 0xd3 0x2 0xfe 0x3 0x24 0x3 0x4f 0x3 0x71 0x3 0x92 0x3 0x9b 0x3 0xa0 0x39 0x5 0xbf 0x3 0xa6 0x3 0xa8 0x39 0x11 0xc0 0x0 0x70 0x0 0x7d 0x0 0x90 0x0 0xa4 0x0 0xb6 0x0 0xd5 0x0 0xee 0x1 0x16 0x39 0x11 0xc1 0x1 0x41 0x1 0x7a 0x1 0xab 0x1 0xf3 0x2 0x36 0x2 0x38 0x2 0x74 0x2 0xaa 0x39 0x11 0xc2 0x2 0xd4 0x3 0x1 0x3 0x26 0x3 0x4f 0x3 0x6e 0x3 0x8e 0x3 0x9b 0x3 0xa0 0x39 0x5 0xc3 0x3 0xa6 0x3 0xa8 0x39 0x11 0xc4 0x1 0xe 0x1 0x13 0x1 0x1a 0x1 0x24 0x1 0x2c 0x1 0x3f 0x1 0x4c 0x1 0x67 0x39 0x11 0xc5 0x1 0x84 0x1 0xad 0x1 0xcf 0x2 0xd 0x2 0x49 0x2 0x4a 0x2 0x83 0x2 0xb5 0x39 0x11 0xc6 0x2 0xdd 0x3 0xc 0x3 0x2e 0x3 0x55 0x3 0x6b 0x3 0x86 0x3 0x97 0x3 0x9b 0x39 0x5 0xc7 0x3 0xa1 0x3 0xa8 0x39 0x6 0xf0 0x55 0xaa 0x52 0x8 0x4 0x39 0x6 0xb1 0x3 0x2 0x2 0x2 0x0 0x39 0x6 0xf0 0x55 0xaa 0x52 0x8 0x6 0x39 0x3 0xb0 0x11 0x11 0x39 0x3 0xb1 0x13 0x13 0x39 0x3 0xb2 0x3 0x3 0x39 0x3 0xb3 0x34 0x34 0x39 0x3 0xb4 0x34 0x34 0x39 0x3 0xb5 0x34 0x34 0x39 0x3 0xb6 0x34 0x34 0x39 0x3 0xb7 0x34 0x34 0x39 0x3 0xb8 0x34 0x34 0x39 0x3 0xb9 0x34 0x34 0x39 0x3 0xba 0x34 0x34 0x39 0x3 0xbb 0x34 0x34 0x39 0x3 0xbc 0x34 0x34 0x39 0x3 0xbd 0x34 0x34 0x39 0x3 0xbe 0x34 0x34 0x39 0x3 0xbf 0x34 0x34 0x39 0x3 0xc0 0x34 0x34 0x39 0x3 0xc1 0x2 0x2 0x39 0x3 0xc2 0x12 0x12 0x39 0x3 0xc3 0x10 0x10 0x39 0x3 0xe5 0x34 0x34 0x39 0x6 0xd8 0x0 0x0 0x0 0x0 0x0 0x39 0x6 0xd9 0x0 0x0 0x0 0x0 0x0 0x39 0x6 0xf0 0x55 0xaa 0x52 0x8 0x5 0x15 0x2 0xc0 0x3 0x15 0x2 0xc1 0x2 0x39 0x3 0xc8 0x1 0x20 0x15 0x2 0xe5 0x3 0x15 0x2 0xe6 0x3 0x15 0x2 0xe7 0x3 0x15 0x2 0xe8 0x3 0x15 0x2 0xe9 0x3 0x39 0x5 0xd1 0x3 0x0 0x3d 0x0 0x39 0x6 0xf0 0x55 0xaa 0x52 0x8 0x3 0x39 0x3 0xb0 0x11 0x0 0x39 0x3 0xb1 0x11 0x0 0x39 0x6 0xb2 0x3 0x0 0x0 0x0 0x0 0x39 0x6 0xb3 0x3 0x0 0x0 0x0 0x0 0x39 0x6 0xba 0x31 0x0 0x0 0x0 0x0 0x15 0x2 0x35 0x0 0x15 0x2 0x51 0xff 0x15 0x2 0x53 0x2c 0x15 0x2 0x55 0x3 0x5 0x1 0x11 0xff 0x78 0x5 0x1 0x29 0xff 0x82 0xff 0xff>;
			init_off = <0x5 0x1 0x28 0xff 0xa 0x5 0x1 0x10 0xff 0x96 0xff 0xff>;
		};

		extern_2 {
			index = <0x2>;
			extern_name = "mipi_default";
			status = "okay";
			type = <0x2>;
			cmd_size = <0xff>;
			init_on = <0x29 0x5 0xff 0xaa 0x55 0x25 0x1 0x23 0x2 0xfc 0x8 0xff 0x1 0x23 0x2 0xfc 0x0 0xff 0x1 0x23 0x2 0x6f 0x21 0x23 0x2 0xf7 0x1 0xff 0x1 0x23 0x2 0x6f 0x21 0x23 0x2 0xf7 0x0 0xff 0x1 0x23 0x2 0x6f 0x1a 0x23 0x2 0xf7 0x5 0xff 0x1 0x29 0x5 0xff 0xaa 0x55 0x25 0x0 0x29 0x6 0xf0 0x55 0xaa 0x52 0x8 0x0 0x29 0x3 0xb1 0x68 0x41 0x23 0x2 0xb5 0x88 0x29 0x6 0xbd 0x2 0xb0 0xc 0x14 0x0 0x23 0x2 0xc8 0x80 0x29 0x6 0xf0 0x55 0xaa 0x52 0x8 0x1 0x29 0x3 0xb3 0x2d 0x2d 0x29 0x3 0xb4 0x19 0x19 0x23 0x2 0xb5 0x6 0x29 0x3 0xb9 0x36 0x36 0x29 0x3 0xba 0x26 0x26 0x29 0x3 0xbc 0xa8 0x1 0x29 0x3 0xbd 0xab 0x1 0x23 0x2 0xc0 0xc 0x29 0x6 0xf0 0x55 0xaa 0x52 0x8 0x2 0x23 0x2 0xee 0x2 0x29 0x7 0xb0 0x0 0x50 0x0 0x52 0x0 0x73 0x23 0x2 0x6f 0x6 0x29 0x7 0xb0 0x0 0x8f 0x0 0xa5 0x0 0xca 0x23 0x2 0x6f 0xc 0x29 0x5 0xb0 0x0 0xea 0x1 0x1b 0x29 0x7 0xb1 0x1 0x42 0x1 0x82 0x1 0xb3 0x23 0x2 0x6f 0x6 0x29 0x7 0xb1 0x2 0x0 0x2 0x41 0x2 0x42 0x23 0x2 0x6f 0xc 0x29 0x5 0xb1 0x2 0x78 0x2 0xb5 0x29 0x7 0xb2 0x2 0xda 0x3 0x12 0x3 0x3a 0x23 0x2 0x6f 0x6 0x29 0x7 0xb2 0x3 0x6e 0x3 0x8d 0x3 0xb1 0x23 0x2 0x6f 0xc 0x29 0x5 0xb2 0x3 0xca 0x3 0xe8 0x29 0x5 0xb3 0x3 0xf4 0x3 0xff 0x29 0x7 0xbc 0x0 0x5 0x0 0x52 0x0 0x73 0x23 0x2 0x6f 0x6 0x29 0x7 0xbc 0x0 0x8f 0x0 0xa5 0x0 0xca 0x23 0x2 0x6f 0xc 0x29 0x5 0xbc 0x0 0xea 0x1 0x1b 0x29 0x7 0xbd 0x1 0x42 0x1 0x82 0x1 0xb3 0x23 0x2 0x6f 0x6 0x29 0x7 0xbd 0x2 0x0 0x2 0x41 0x2 0x42 0x23 0x2 0x6f 0xc 0x29 0x5 0xbd 0x2 0x78 0x2 0xb5 0x29 0x7 0xbe 0x2 0xda 0x3 0x12 0x3 0x3a 0x23 0x2 0x6f 0x6 0x29 0x7 0xbe 0x3 0x6e 0x3 0x8d 0x3 0xb1 0x23 0x2 0x6f 0xc 0x29 0x5 0xbe 0x3 0xca 0x3 0xe8 0x29 0x5 0xbf 0x3 0xf4 0x3 0xff 0x29 0x6 0xf0 0x55 0xaa 0x52 0x8 0x3 0x29 0x6 0xb2 0x5 0x0 0x0 0x0 0x0 0x29 0x6 0xb6 0x5 0x0 0x0 0x0 0x0 0x29 0x6 0xb7 0x5 0x0 0x0 0x0 0x0 0x29 0x6 0xba 0x57 0x0 0x0 0x0 0x0 0x29 0x6 0xbb 0x57 0x0 0x0 0x0 0x0 0x29 0x5 0xc0 0x0 0x34 0x0 0x0 0x29 0x5 0xc1 0x0 0x0 0x34 0x0 0x23 0x2 0xc4 0x40 0x29 0x6 0xf0 0x55 0xaa 0x52 0x8 0x5 0x29 0x3 0xb0 0x17 0x6 0x29 0x3 0xb1 0x17 0x6 0x29 0x3 0xb2 0x17 0x6 0x29 0x3 0xb3 0x17 0x6 0x29 0x3 0xb4 0x17 0x6 0x29 0x6 0xbd 0x3 0x1 0x3 0x3 0x1 0x23 0x2 0xc0 0x5 0x23 0x2 0xc4 0x82 0x23 0x2 0xc5 0xa2 0x29 0x3 0xc8 0x3 0x30 0x29 0x3 0xc9 0x3 0x31 0x29 0x4 0xcc 0x0 0x0 0x3c 0x29 0x4 0xcd 0x0 0x0 0x3c 0x29 0x6 0xd1 0x0 0x44 0x9 0x0 0x0 0x29 0x6 0xd2 0x0 0x4 0xb 0x0 0x0 0x29 0x6 0xf0 0x55 0xaa 0x52 0x8 0x6 0x29 0x3 0xb0 0xb 0x2d 0x29 0x3 0xb1 0x2d 0x9 0x29 0x3 0xb2 0x2a 0x29 0x29 0x3 0xb3 0x34 0x1b 0x29 0x3 0xb4 0x19 0x17 0x29 0x3 0xb5 0x15 0x13 0x29 0x3 0xb6 0x11 0x1 0x29 0x3 0xb7 0x34 0x34 0x29 0x3 0xb8 0x34 0x2d 0x29 0x3 0xb9 0x2d 0x34 0x29 0x3 0xba 0x2d 0x2d 0x29 0x3 0xbb 0x34 0x34 0x29 0x3 0xbc 0x34 0x34 0x29 0x3 0xbd 0x0 0x10 0x29 0x3 0xbe 0x12 0x14 0x29 0x3 0xbf 0x16 0x18 0x29 0x3 0xc0 0x1a 0x34 0x29 0x3 0xc1 0x29 0x2a 0x29 0x3 0xc2 0x8 0x2d 0x29 0x3 0xc3 0x2d 0xa 0x29 0x3 0xc4 0xa 0x2d 0x29 0x3 0xc5 0x2d 0x0 0x29 0x3 0xc6 0x2a 0x29 0x29 0x3 0xc7 0x34 0x14 0x29 0x3 0xc8 0x16 0x18 0x29 0x3 0xc9 0x1a 0x10 0x29 0x3 0xca 0x12 0x8 0x29 0x3 0xcb 0x34 0x34 0x29 0x3 0xcc 0x34 0x2d 0x29 0x3 0xcd 0x2d 0x34 0x29 0x3 0xce 0x2d 0x2d 0x29 0x3 0xcf 0x34 0x34 0x29 0x3 0xd0 0x34 0x34 0x29 0x3 0xd1 0x9 0x13 0x29 0x3 0xd2 0x11 0x1b 0x29 0x3 0xd3 0x19 0x17 0x29 0x3 0xd4 0x15 0x34 0x29 0x3 0xd5 0x29 0x2a 0x29 0x3 0xd6 0x1 0x2d 0x29 0x3 0xd7 0x2d 0xb 0x29 0x6 0xd8 0x0 0x0 0x0 0x0 0x0 0x29 0x6 0xd9 0x0 0x0 0x0 0x0 0x0 0x29 0x3 0xe5 0x34 0x34 0x29 0x3 0xe6 0x34 0x34 0x23 0x2 0xe7 0x0 0x29 0x3 0xe8 0x34 0x34 0x29 0x3 0xe9 0x34 0x34 0x23 0x2 0xea 0x0 0x29 0x6 0xf0 0x55 0xaa 0x52 0x0 0x0 0x13 0x1 0x35 0x13 0x1 0x11 0xff 0x78 0x13 0x1 0x29 0xff 0x14 0xff 0xff>;
			init_off = <0x5 0x1 0x28 0xff 0xa 0x5 0x1 0x10 0xff 0x96 0xff 0xff>;
		};

		extern_3 {
			index = <0x3>;
			extern_name = "mipi_default";
			status = "okay";
			type = <0x2>;
			cmd_size = <0xff>;
			init_on = <0x29 0x6 0xf0 0x55 0xaa 0x52 0x8 0x3 0x29 0xa 0x90 0x3 0x14 0x9 0x0 0x0 0x0 0x38 0x0 0x0 0x29 0xa 0x91 0x0 0x0 0x0 0x0 0x0 0x0 0x0 0x0 0x0 0x29 0xc 0x92 0x40 0xb 0xc 0xd 0xe 0x0 0x38 0x0 0x10 0x3 0x4 0x29 0x9 0x94 0x0 0x8 0xb 0x3 0xd2 0x3 0xd3 0xc 0x29 0x11 0x95 0x0 0x0 0x0 0x0 0x0 0x0 0x0 0x0 0x0 0x0 0x0 0x0 0x0 0x0 0x0 0x0 0x29 0x3 0x99 0x0 0x0 0x29 0xc 0x9a 0x0 0x0 0x0 0x0 0x0 0x0 0x0 0x0 0x0 0x0 0x0 0x29 0x7 0x9b 0x1 0x38 0x0 0x0 0x0 0x0 0x29 0x3 0x9c 0x0 0x0 0x29 0x9 0x9d 0x10 0x10 0x10 0x10 0x10 0x10 0x0 0x0 0x29 0x3 0x9e 0x0 0x0 0x29 0xb 0xa0 0x9f 0x1f 0x8 0x1f 0xa 0x1f 0x0 0x1f 0x14 0x1f 0x29 0xb 0xa1 0x15 0x1f 0x1f 0x1f 0x1f 0x1f 0x1f 0x1f 0x1f 0x1f 0x29 0xb 0xa2 0x1f 0x1f 0x1f 0x1f 0x1f 0x1f 0x1f 0x1f 0x1f 0x1f 0x29 0xb 0xa4 0x1f 0x1f 0x1f 0x1f 0x1f 0x1f 0x1f 0x1f 0x1f 0x1f 0x29 0xb 0xa5 0x1f 0x1f 0x1f 0x1f 0x1f 0x1f 0x1f 0x1f 0x1f 0x15 0x29 0xb 0xa6 0x1f 0x14 0x1f 0x1 0x1f 0xb 0x1f 0x9 0x1f 0x1f 0x29 0xb 0xa7 0x1f 0x1f 0xb 0x1f 0x9 0x1f 0x1 0x1f 0x15 0x1f 0x29 0xb 0xa8 0x14 0x1f 0x1f 0x1f 0x1f 0x1f 0x1f 0x1f 0x1f 0x1f 0x29 0xb 0xa9 0x1f 0x1f 0x1f 0x1f 0x1f 0x1f 0x1f 0x1f 0x1f 0x1f 0x29 0xb 0xab 0x1f 0x1f 0x1f 0x1f 0x1f 0x1f 0x1f 0x1f 0x1f 0x1f 0x29 0xb 0xac 0x1f 0x1f 0x1f 0x1f 0x1f 0x1f 0x1f 0x1f 0x1f 0x14 0x29 0xb 0xad 0x1f 0x15 0x1f 0x0 0x1f 0x8 0x1f 0xa 0x1f 0x1f 0x29 0x6 0xf0 0x55 0xaa 0x52 0x8 0x0 0x29 0x4 0xbc 0x0 0x0 0x0 0x29 0x5 0xb8 0x1 0xaf 0x8f 0x8f 0x29 0x6 0xf0 0x55 0xaa 0x52 0x8 0x1 0x29 0x11 0xd1 0x0 0x0 0x0 0x9 0x0 0x1f 0x0 0x30 0x0 0x3f 0x0 0x5d 0x0 0x79 0x0 0xa7 0x29 0x11 0xd2 0x0 0xcf 0x1 0x12 0x1 0x49 0x1 0xa1 0x1 0xeb 0x1 0xed 0x2 0x2f 0x2 0x74 0x29 0x11 0xd3 0x2 0x9f 0x2 0xd5 0x2 0xfb 0x3 0x2c 0x3 0x4b 0x3 0x73 0x3 0x8c 0x3 0xa5 0x29 0x5 0xd4 0x3 0xc5 0x3 0xff 0x29 0x11 0xd5 0x0 0x0 0x0 0x9 0x0 0x1f 0x0 0x30 0x0 0x3f 0x0 0x5d 0x0 0x79 0x0 0xa7 0x29 0x11 0xd6 0x0 0xcf 0x1 0x12 0x1 0x49 0x1 0xa1 0x1 0xeb 0x1 0xed 0x2 0x2f 0x2 0x74 0x29 0x11 0xd7 0x2 0x9f 0x2 0xd5 0x2 0xfb 0x3 0x2c 0x3 0x4b 0x3 0x73 0x3 0x8c 0x3 0xa5 0x29 0x5 0xd8 0x3 0xc5 0x3 0xff 0x29 0x11 0xd9 0x0 0x0 0x0 0x9 0x0 0x1f 0x0 0x30 0x0 0x3f 0x0 0x5d 0x0 0x79 0x0 0xa7 0x29 0x11 0xdd 0x0 0xcf 0x1 0x12 0x1 0x49 0x1 0xa1 0x1 0xeb 0x1 0xed 0x2 0x2f 0x2 0x74 0x29 0x11 0xde 0x2 0x9f 0x2 0xd5 0x2 0xfb 0x3 0x2c 0x3 0x4b 0x3 0x73 0x3 0x8c 0x3 0xa5 0x29 0x5 0xdf 0x3 0xc5 0x3 0xff 0x29 0x11 0xe0 0x0 0x0 0x0 0x9 0x0 0x1f 0x0 0x30 0x0 0x3f 0x0 0x5d 0x0 0x79 0x0 0xa7 0x29 0x11 0xe1 0x0 0xcf 0x1 0x12 0x1 0x49 0x1 0xa1 0x1 0xeb 0x1 0xed 0x2 0x2f 0x2 0x74 0x29 0x11 0xe2 0x2 0x9f 0x2 0xd5 0x2 0xfb 0x3 0x2c 0x3 0x4b 0x3 0x73 0x3 0x8c 0x3 0xa5 0x29 0x5 0xe3 0x3 0xc5 0x3 0xff 0x29 0x11 0xe4 0x0 0x0 0x0 0x9 0x0 0x1f 0x0 0x30 0x0 0x3f 0x0 0x5d 0x0 0x79 0x0 0xa7 0x29 0x11 0xe5 0x0 0xcf 0x1 0x12 0x1 0x49 0x1 0xa1 0x1 0xeb 0x1 0xed 0x2 0x2f 0x2 0x74 0x29 0x11 0xe6 0x2 0x9f 0x2 0xd5 0x2 0xfb 0x3 0x2c 0x3 0x4b 0x3 0x73 0x3 0x8c 0x3 0xa5 0x29 0x5 0xe7 0x3 0xc5 0x3 0xff 0x29 0x11 0xe8 0x0 0x0 0x0 0x9 0x0 0x1f 0x0 0x30 0x0 0x3f 0x0 0x5d 0x0 0x79 0x0 0xa7 0x29 0x11 0xe9 0x0 0xcf 0x1 0x12 0x1 0x49 0x1 0xa1 0x1 0xeb 0x1 0xed 0x2 0x2f 0x2 0x74 0x29 0x11 0xea 0x2 0x9f 0x2 0xd5 0x2 0xfb 0x3 0x2c 0x3 0x4b 0x3 0x73 0x3 0x8c 0x3 0xa5 0x29 0x5 0xeb 0x3 0xc5 0x3 0xff 0x29 0x4 0xb0 0x5 0x5 0x5 0x29 0x4 0xb1 0x5 0x5 0x5 0x29 0x4 0xb3 0x10 0x10 0x10 0x29 0x4 0xb4 0x6 0x6 0x6 0x29 0x4 0xb6 0x44 0x44 0x44 0x29 0x4 0xb7 0x34 0x34 0x34 0x29 0x4 0xb8 0x34 0x34 0x34 0x29 0x4 0xb9 0x24 0x24 0x24 0x29 0x4 0xba 0x24 0x24 0x24 0x29 0x4 0xbc 0x0 0x70 0x0 0x29 0x4 0xbd 0x0 0x70 0x0 0x23 0x2 0xbe 0x50 0x23 0x2 0x35 0x0 0x13 0x1 0x11 0xff 0xc8 0x13 0x1 0x29 0xff 0xc8 0xff 0xff>;
			init_off = <0x5 0x1 0x28 0xff 0xa 0x5 0x1 0x10 0xff 0x96 0xff 0xff>;
		};

		extern_4 {
			index = <0x4>;
			extern_name = "mipi_default";
			status = "okay";
			type = <0x2>;
			cmd_size = <0xff>;
			init_on = <0x23 0x2 0xe0 0x0 0x23 0x2 0xe1 0x93 0x23 0x2 0xe2 0x65 0x23 0x2 0xe3 0xf8 0x23 0x2 0xe0 0x1 0x23 0x2 0x0 0x0 0x23 0x2 0x1 0x90 0x23 0x2 0x3 0x0 0x23 0x2 0x4 0x90 0x23 0x2 0x17 0x0 0x23 0x2 0x18 0xb0 0x23 0x2 0x19 0x1 0x23 0x2 0x1a 0x0 0x23 0x2 0x1b 0xb0 0x23 0x2 0x1c 0x1 0x23 0x2 0x1f 0x3e 0x23 0x2 0x20 0x2f 0x23 0x2 0x21 0x2f 0x23 0x2 0x22 0xe 0x23 0x2 0x37 0x69 0x23 0x2 0x38 0x5 0x23 0x2 0x39 0x0 0x23 0x2 0x3a 0x1 0x23 0x2 0x3c 0x90 0x23 0x2 0x3d 0xff 0x23 0x2 0x3e 0xff 0x23 0x2 0x3f 0xff 0x23 0x2 0x40 0x2 0x23 0x2 0x41 0x80 0x23 0x2 0x42 0x99 0x23 0x2 0x43 0x6 0x23 0x2 0x44 0x9 0x23 0x2 0x45 0x3c 0x23 0x2 0x4b 0x4 0x23 0x2 0x55 0xf 0x23 0x2 0x56 0x1 0x23 0x2 0x57 0x89 0x23 0x2 0x58 0xa 0x23 0x2 0x59 0xa 0x23 0x2 0x5a 0x27 0x23 0x2 0x5b 0x15 0x23 0x2 0x5d 0x7c 0x23 0x2 0x5e 0x67 0x23 0x2 0x5f 0x58 0x23 0x2 0x60 0x4c 0x23 0x2 0x61 0x48 0x23 0x2 0x62 0x38 0x23 0x2 0x63 0x3c 0x23 0x2 0x64 0x24 0x23 0x2 0x65 0x3b 0x23 0x2 0x66 0x38 0x23 0x2 0x67 0x36 0x23 0x2 0x68 0x53 0x23 0x2 0x69 0x3f 0x23 0x2 0x6a 0x44 0x23 0x2 0x6b 0x35 0x23 0x2 0x6c 0x2e 0x23 0x2 0x6d 0x1f 0x23 0x2 0x6e 0xc 0x23 0x2 0x6f 0x0 0x23 0x2 0x70 0x7c 0x23 0x2 0x71 0x67 0x23 0x2 0x72 0x58 0x23 0x2 0x73 0x4c 0x23 0x2 0x74 0x48 0x23 0x2 0x75 0x38 0x23 0x2 0x76 0x3c 0x23 0x2 0x77 0x24 0x23 0x2 0x78 0x3b 0x23 0x2 0x79 0x38 0x23 0x2 0x7a 0x36 0x23 0x2 0x7b 0x53 0x23 0x2 0x7c 0x3f 0x23 0x2 0x7d 0x44 0x23 0x2 0x7e 0x35 0x23 0x2 0x7f 0x2e 0x23 0x2 0x80 0x1f 0x23 0x2 0x81 0xc 0x23 0x2 0x82 0x0 0x23 0x2 0xe0 0x2 0x23 0x2 0x0 0x45 0x23 0x2 0x1 0x45 0x23 0x2 0x2 0x47 0x23 0x2 0x3 0x47 0x23 0x2 0x4 0x41 0x23 0x2 0x5 0x41 0x23 0x2 0x6 0x1f 0x23 0x2 0x7 0x1f 0x23 0x2 0x8 0x1f 0x23 0x2 0x9 0x1f 0x23 0x2 0xa 0x1f 0x23 0x2 0xb 0x1f 0x23 0x2 0xc 0x1f 0x23 0x2 0xd 0x1d 0x23 0x2 0xe 0x1d 0x23 0x2 0xf 0x1d 0x23 0x2 0x10 0x1f 0x23 0x2 0x11 0x1f 0x23 0x2 0x12 0x1f 0x23 0x2 0x13 0x1f 0x23 0x2 0x14 0x1f 0x23 0x2 0x15 0x1f 0x23 0x2 0x16 0x44 0x23 0x2 0x17 0x44 0x23 0x2 0x18 0x46 0x23 0x2 0x19 0x46 0x23 0x2 0x1a 0x40 0x23 0x2 0x1b 0x40 0x23 0x2 0x1c 0x1f 0x23 0x2 0x1d 0x1f 0x23 0x2 0x1e 0x1f 0x23 0x2 0x1f 0x1f 0x23 0x2 0x20 0x1f 0x23 0x2 0x21 0x1f 0x23 0x2 0x22 0x1f 0x23 0x2 0x23 0x1d 0x23 0x2 0x24 0x1d 0x23 0x2 0x25 0x1d 0x23 0x2 0x26 0x1f 0x23 0x2 0x27 0x1f 0x23 0x2 0x28 0x1f 0x23 0x2 0x29 0x1f 0x23 0x2 0x2a 0x1f 0x23 0x2 0x2b 0x1f 0x23 0x2 0x58 0x40 0x23 0x2 0x59 0x0 0x23 0x2 0x5a 0x0 0x23 0x2 0x5b 0x10 0x23 0x2 0x5c 0x6 0x23 0x2 0x5d 0x20 0x23 0x2 0x5e 0x0 0x23 0x2 0x5f 0x0 0x23 0x2 0x61 0x0 0x23 0x2 0x62 0x0 0x23 0x2 0x63 0x7a 0x23 0x2 0x64 0x7a 0x23 0x2 0x65 0x0 0x23 0x2 0x66 0x0 0x23 0x2 0x67 0x32 0x23 0x2 0x68 0x8 0x23 0x2 0x69 0x7a 0x23 0x2 0x6a 0x7a 0x23 0x2 0x6b 0x0 0x23 0x2 0x6c 0x0 0x23 0x2 0x6d 0x4 0x23 0x2 0x6e 0x4 0x23 0x2 0x6f 0x88 0x23 0x2 0x70 0x0 0x23 0x2 0x71 0x0 0x23 0x2 0x72 0x6 0x23 0x2 0x73 0x7b 0x23 0x2 0x74 0x0 0x23 0x2 0x75 0x7 0x23 0x2 0x76 0x0 0x23 0x2 0x77 0x5d 0x23 0x2 0x78 0x17 0x23 0x2 0x79 0x1f 0x23 0x2 0x7a 0x0 0x23 0x2 0x7b 0x0 0x23 0x2 0x7c 0x0 0x23 0x2 0x7d 0x3 0x23 0x2 0x7e 0x7b 0x23 0x2 0xe0 0x3 0x23 0x2 0xaf 0x20 0x23 0x2 0xe0 0x4 0x23 0x2 0x9 0x11 0x23 0x2 0xe 0x48 0x23 0x2 0x2b 0x2b 0x23 0x2 0x2e 0x44 0x23 0x2 0x41 0xff 0x23 0x2 0xe0 0x0 0x23 0x2 0xe6 0x2 0x23 0x2 0xe7 0xc 0x5 0x1 0x11 0xff 0x78 0x23 0x2 0xe0 0x3 0x23 0x2 0x2b 0x1 0x23 0x2 0x2c 0x0 0x23 0x2 0x30 0x3 0x23 0x2 0x31 0xcc 0x23 0x2 0x32 0x3 0x23 0x2 0x33 0xc9 0x23 0x2 0x34 0x3 0x23 0x2 0x35 0xc0 0x23 0x2 0x36 0x3 0x23 0x2 0x37 0xb3 0x23 0x2 0x38 0x3 0x23 0x2 0x39 0xab 0x23 0x2 0x3a 0x3 0x23 0x2 0x3b 0x9d 0x23 0x2 0x3c 0x3 0x23 0x2 0x3d 0x8f 0x23 0x2 0x3e 0x3 0x23 0x2 0x3f 0x6d 0x23 0x2 0x40 0x3 0x23 0x2 0x41 0x51 0x23 0x2 0x42 0x3 0x23 0x2 0x43 0x17 0x23 0x2 0x44 0x2 0x23 0x2 0x45 0xd8 0x23 0x2 0x46 0x2 0x23 0x2 0x47 0x60 0x23 0x2 0x48 0x1 0x23 0x2 0x49 0xeb 0x23 0x2 0x4a 0x1 0x23 0x2 0x4b 0xe5 0x23 0x2 0x4c 0x1 0x23 0x2 0x4d 0x6c 0x23 0x2 0x4e 0x0 0x23 0x2 0x4f 0xf2 0x23 0x2 0x50 0x0 0x23 0x2 0x51 0xb4 0x23 0x2 0x52 0x0 0x23 0x2 0x53 0x74 0x23 0x2 0x54 0x0 0x23 0x2 0x55 0x54 0x23 0x2 0x56 0x0 0x23 0x2 0x57 0x34 0x23 0x2 0x58 0x0 0x23 0x2 0x59 0x26 0x23 0x2 0x5a 0x0 0x23 0x2 0x5b 0x18 0x23 0x2 0x5c 0x0 0x23 0x2 0x5d 0x11 0x23 0x2 0x5e 0x0 0x23 0x2 0x5f 0xa 0x23 0x2 0x60 0x0 0x23 0x2 0x61 0x3 0x23 0x2 0x62 0x0 0x23 0x2 0x63 0x0 0x23 0x2 0x64 0x3 0x23 0x2 0x65 0x9e 0x23 0x2 0x66 0x3 0x23 0x2 0x67 0x9b 0x23 0x2 0x68 0x3 0x23 0x2 0x69 0x94 0x23 0x2 0x6a 0x3 0x23 0x2 0x6b 0x8c 0x23 0x2 0x6c 0x3 0x23 0x2 0x6d 0x85 0x23 0x2 0x6e 0x3 0x23 0x2 0x6f 0x76 0x23 0x2 0x70 0x3 0x23 0x2 0x71 0x67 0x23 0x2 0x72 0x3 0x23 0x2 0x73 0x4b 0x23 0x2 0x74 0x3 0x23 0x2 0x75 0x2e 0x23 0x2 0x76 0x2 0x23 0x2 0x77 0xf7 0x23 0x2 0x78 0x2 0x23 0x2 0x79 0xb8 0x23 0x2 0x7a 0x2 0x23 0x2 0x7b 0x46 0x23 0x2 0x7c 0x1 0x23 0x2 0x7d 0xd6 0x23 0x2 0x7e 0x1 0x23 0x2 0x7f 0xd0 0x23 0x2 0x80 0x1 0x23 0x2 0x81 0x5c 0x23 0x2 0x82 0x0 0x23 0x2 0x83 0xe7 0x23 0x2 0x84 0x0 0x23 0x2 0x85 0xaa 0x23 0x2 0x86 0x0 0x23 0x2 0x87 0x74 0x23 0x2 0x88 0x0 0x23 0x2 0x89 0x5a 0x23 0x2 0x8a 0x0 0x23 0x2 0x8b 0x3c 0x23 0x2 0x8c 0x0 0x23 0x2 0x8d 0x2c 0x23 0x2 0x8e 0x0 0x23 0x2 0x8f 0x1c 0x23 0x2 0x90 0x0 0x23 0x2 0x91 0x14 0x23 0x2 0x92 0x0 0x23 0x2 0x93 0xc 0x23 0x2 0x94 0x0 0x23 0x2 0x95 0x4 0x23 0x2 0x96 0x0 0x23 0x2 0x97 0x0 0x23 0x2 0xe0 0x0 0x5 0x1 0x29 0xff 0x5 0xff 0xff>;
			init_off = <0x5 0x1 0x28 0xff 0xa 0x5 0x1 0x10 0xff 0x96 0xff 0xff>;
		};

		extern_5 {
			index = <0x5>;
			extern_name = "mipi_default";
			status = "okay";
			type = <0x2>;
			cmd_size = <0xff>;
			init_on = <0x23 0x2 0xe0 0x0 0x23 0x2 0xe1 0x93 0x23 0x2 0xe2 0x65 0x23 0x2 0xe3 0xf8 0x23 0x2 0x80 0x3 0x23 0x2 0xe0 0x1 0x23 0x2 0xc 0x74 0x23 0x2 0x17 0x0 0x23 0x2 0x18 0xef 0x23 0x2 0x19 0x0 0x23 0x2 0x1a 0x0 0x23 0x2 0x1b 0xef 0x23 0x2 0x1c 0x0 0x23 0x2 0x1f 0x70 0x23 0x2 0x20 0x2d 0x23 0x2 0x21 0x2d 0x23 0x2 0x22 0x7e 0x23 0x2 0x26 0xf3 0x23 0x2 0x37 0x9 0x23 0x2 0x38 0x4 0x23 0x2 0x39 0x0 0x23 0x2 0x3a 0x1 0x23 0x2 0x3c 0x90 0x23 0x2 0x3d 0xff 0x23 0x2 0x3e 0xff 0x23 0x2 0x3f 0xff 0x23 0x2 0x40 0x2 0x23 0x2 0x41 0x80 0x23 0x2 0x42 0x99 0x23 0x2 0x43 0x14 0x23 0x2 0x44 0x19 0x23 0x2 0x45 0x5a 0x23 0x2 0x4b 0x4 0x23 0x2 0x55 0x2 0x23 0x2 0x56 0x1 0x23 0x2 0x57 0x69 0x23 0x2 0x58 0xa 0x23 0x2 0x59 0xa 0x23 0x2 0x5a 0x2e 0x23 0x2 0x5b 0x19 0x23 0x2 0x5c 0x15 0x23 0x2 0x5d 0x77 0x23 0x2 0x5e 0x56 0x23 0x2 0x5f 0x45 0x23 0x2 0x60 0x38 0x23 0x2 0x61 0x35 0x23 0x2 0x62 0x27 0x23 0x2 0x63 0x2d 0x23 0x2 0x64 0x18 0x23 0x2 0x65 0x33 0x23 0x2 0x66 0x34 0x23 0x2 0x67 0x35 0x23 0x2 0x68 0x56 0x23 0x2 0x69 0x45 0x23 0x2 0x6a 0x4f 0x23 0x2 0x6b 0x42 0x23 0x2 0x6c 0x40 0x23 0x2 0x6d 0x34 0x23 0x2 0x6e 0x25 0x23 0x2 0x6f 0x2 0x23 0x2 0x70 0x77 0x23 0x2 0x71 0x56 0x23 0x2 0x72 0x45 0x23 0x2 0x73 0x38 0x23 0x2 0x74 0x35 0x23 0x2 0x75 0x27 0x23 0x2 0x76 0x2d 0x23 0x2 0x77 0x18 0x23 0x2 0x78 0x33 0x23 0x2 0x79 0x34 0x23 0x2 0x7a 0x35 0x23 0x2 0x7b 0x56 0x23 0x2 0x7c 0x45 0x23 0x2 0x7d 0x4f 0x23 0x2 0x7e 0x42 0x23 0x2 0x7f 0x40 0x23 0x2 0x80 0x34 0x23 0x2 0x81 0x25 0x23 0x2 0x82 0x2 0x23 0x2 0xe0 0x2 0x23 0x2 0x0 0x53 0x23 0x2 0x1 0x55 0x23 0x2 0x2 0x55 0x23 0x2 0x3 0x51 0x23 0x2 0x4 0x77 0x23 0x2 0x5 0x57 0x23 0x2 0x6 0x1f 0x23 0x2 0x7 0x4f 0x23 0x2 0x8 0x4d 0x23 0x2 0x9 0x1f 0x23 0x2 0xa 0x4b 0x23 0x2 0xb 0x49 0x23 0x2 0xc 0x1f 0x23 0x2 0xd 0x47 0x23 0x2 0xe 0x45 0x23 0x2 0xf 0x41 0x23 0x2 0x10 0x1f 0x23 0x2 0x11 0x1f 0x23 0x2 0x12 0x1f 0x23 0x2 0x13 0x55 0x23 0x2 0x14 0x1f 0x23 0x2 0x15 0x1f 0x23 0x2 0x16 0x52 0x23 0x2 0x17 0x55 0x23 0x2 0x18 0x55 0x23 0x2 0x19 0x50 0x23 0x2 0x1a 0x77 0x23 0x2 0x1b 0x57 0x23 0x2 0x1c 0x1f 0x23 0x2 0x1d 0x4e 0x23 0x2 0x1e 0x4c 0x23 0x2 0x1f 0x1f 0x23 0x2 0x20 0x4a 0x23 0x2 0x21 0x48 0x23 0x2 0x22 0x1f 0x23 0x2 0x23 0x46 0x23 0x2 0x24 0x44 0x23 0x2 0x25 0x40 0x23 0x2 0x26 0x1f 0x23 0x2 0x27 0x1f 0x23 0x2 0x28 0x1f 0x23 0x2 0x29 0x1f 0x23 0x2 0x2a 0x1f 0x23 0x2 0x2b 0x55 0x23 0x2 0x2c 0x12 0x23 0x2 0x2d 0x15 0x23 0x2 0x2e 0x15 0x23 0x2 0x2f 0x0 0x23 0x2 0x30 0x37 0x23 0x2 0x31 0x17 0x23 0x2 0x32 0x1f 0x23 0x2 0x33 0x8 0x23 0x2 0x34 0xa 0x23 0x2 0x35 0x1f 0x23 0x2 0x36 0xc 0x23 0x2 0x37 0xe 0x23 0x2 0x38 0x1f 0x23 0x2 0x39 0x4 0x23 0x2 0x3a 0x6 0x23 0x2 0x3b 0x10 0x23 0x2 0x3c 0x1f 0x23 0x2 0x3d 0x1f 0x23 0x2 0x3e 0x1f 0x23 0x2 0x3f 0x15 0x23 0x2 0x40 0x1f 0x23 0x2 0x41 0x1f 0x23 0x2 0x42 0x13 0x23 0x2 0x43 0x15 0x23 0x2 0x44 0x15 0x23 0x2 0x45 0x1 0x23 0x2 0x46 0x37 0x23 0x2 0x47 0x17 0x23 0x2 0x48 0x1f 0x23 0x2 0x49 0x9 0x23 0x2 0x4a 0xb 0x23 0x2 0x4b 0x1f 0x23 0x2 0x4c 0xd 0x23 0x2 0x4d 0xf 0x23 0x2 0x4e 0x1f 0x23 0x2 0x4f 0x5 0x23 0x2 0x50 0x7 0x23 0x2 0x51 0x11 0x23 0x2 0x52 0x1f 0x23 0x2 0x53 0x1f 0x23 0x2 0x54 0x1f 0x23 0x2 0x55 0x1f 0x23 0x2 0x56 0x1f 0x23 0x2 0x57 0x15 0x23 0x2 0x58 0x40 0x23 0x2 0x59 0x0 0x23 0x2 0x5a 0x0 0x23 0x2 0x5b 0x10 0x23 0x2 0x5c 0x14 0x23 0x2 0x5d 0x40 0x23 0x2 0x5e 0x1 0x23 0x2 0x5f 0x2 0x23 0x2 0x60 0x40 0x23 0x2 0x61 0x3 0x23 0x2 0x62 0x4 0x23 0x2 0x63 0x7a 0x23 0x2 0x64 0x7a 0x23 0x2 0x65 0x74 0x23 0x2 0x66 0x16 0x23 0x2 0x67 0xb4 0x23 0x2 0x68 0x16 0x23 0x2 0x69 0x7a 0x23 0x2 0x6a 0x7a 0x23 0x2 0x6b 0xc 0x23 0x2 0x6c 0x0 0x23 0x2 0x6d 0x4 0x23 0x2 0x6e 0x4 0x23 0x2 0x6f 0x88 0x23 0x2 0x70 0x0 0x23 0x2 0x71 0x0 0x23 0x2 0x72 0x6 0x23 0x2 0x73 0x7b 0x23 0x2 0x74 0x0 0x23 0x2 0x75 0xbc 0x23 0x2 0x76 0x0 0x23 0x2 0x77 0x4 0x23 0x2 0x78 0x2c 0x23 0x2 0x79 0x0 0x23 0x2 0x7a 0x0 0x23 0x2 0x7b 0x0 0x23 0x2 0x7c 0x0 0x23 0x2 0x7d 0x3 0x23 0x2 0x7e 0x7b 0x23 0x2 0xe0 0x4 0x23 0x2 0x9 0x11 0x23 0x2 0xe 0x48 0x23 0x2 0x2b 0x2b 0x23 0x2 0x2e 0x44 0x23 0x2 0xe0 0x0 0x23 0x2 0xe6 0x2 0x23 0x2 0xe7 0xc 0x5 0x1 0x11 0xff 0x78 0x5 0x1 0x29 0x5 0x1 0x35 0xff 0x14 0xff 0xff>;
			init_off = <0x5 0x1 0x28 0xff 0xa 0x5 0x1 0x10 0xff 0x96 0xff 0xff>;
		};
	};

	backlight {
		compatible = "amlogic, backlight-g12a";
		dev_name = "backlight";
		status = "okay";
		key_valid = <0x0>;
		pinctrl-names = "pwm_on";
		pinctrl-0 = <0x67>;
		pinctrl_version = <0x2>;
		bl_pwm_config = <0x68>;
		bl-gpios = <0x16 0x15 0x0 0x16 0x16 0x0>;
		bl_gpio_names = "GPIOH_4", "GPIOH_5";

		backlight_0 {
			index = <0x0>;
			bl_name = "backlight_pwm";
			bl_level_default_uboot_kernel = <0x64 0x64>;
			bl_level_attr = <0xff 0xa 0x80 0x80>;
			bl_ctrl_method = <0x1>;
			bl_power_attr = <0x0 0x1 0x0 0xc8 0xc8>;
			bl_pwm_port = "PWM_F";
			bl_pwm_attr = <0x0 0xb4 0x64 0x19>;
			bl_pwm_power = <0x1 0x1 0xa 0xa>;
			bl_pwm_en_sequence_reverse = <0x0>;
		};

		backlight_1 {
			index = <0x1>;
			bl_name = "bl_extern";
			bl_level_default_uboot_kernel = <0x64 0x64>;
			bl_level_attr = <0xff 0xa 0x80 0x80>;
			bl_ctrl_method = <0x4>;
			bl_power_attr = <0x1 0x1 0x0 0xc8 0xc8>;
			bl_extern_index = <0x0>;
		};
	};

	bl_pwm_conf {
		linux,phandle = <0x68>;
		phandle = <0x68>;

		pwm_channel_0 {
			pwm_port_index = <0x5>;
			pwms = <0x69 0x1 0x7558 0x0>;
		};
	};

	bl_extern {
		compatible = "amlogic, bl_extern";
		dev_name = "bl_extern";
		status = "disabled";

		extern_0 {
			index = <0x0>;
			extern_name = "i2c_lp8556";
			type = <0x0>;
			i2c_address = <0x2c>;
			i2c_bus = "i2c_bus_c";
			dim_max_min = <0xff 0xa>;
		};

		extern_1 {
			index = <0x1>;
			extern_name = "mipi_lt070me05";
			type = <0x2>;
			dim_max_min = <0xff 0xa>;
		};
	};

	aliases {
		serial0 = "/soc/aobus@ff800000/serial@3000";
		serial1 = "/serial@ffd24000";
		serial2 = "/serial@ffd23000";
		serial3 = "/serial@ffd22000";
		serial4 = "/soc/aobus@ff800000/serial@4000";
		tsensor0 = "/p_tsensor@ff634594";
		tsensor1 = "/d_tsensor@ff800228";
		i2c0 = "/soc/cbus@ffd00000/i2c@1f000";
		i2c1 = "/soc/cbus@ffd00000/i2c@1e000";
		i2c2 = "/soc/cbus@ffd00000/i2c@1d000";
		i2c3 = "/soc/cbus@ffd00000/i2c@1c000";
		i2c4 = "/soc/aobus@ff800000/i2c@5000";
	};

	memory@00000000 {
		device_type = "memory";
		linux,usable-memory = <0x0 0x100000 0x0 0x7ff00000>;
	};

	reserved-memory {
		#address-cells = <0x2>;
		#size-cells = <0x2>;
		ranges;

		ramoops@0x07400000 {
			compatible = "ramoops";
			reg = <0x0 0x7400000 0x0 0x100000>;
			record-size = <0x8000>;
			console-size = <0x8000>;
			ftrace-size = <0x0>;
			pmsg-size = <0x8000>;
		};

		linux,secmon {
			compatible = "shared-dma-pool";
			reusable;
			size = <0x0 0x400000>;
			alignment = <0x0 0x400000>;
			alloc-ranges = <0x0 0x5000000 0x0 0x400000>;
			linux,phandle = <0xf>;
			phandle = <0xf>;
		};

		linux,secos {
			status = "disable";
			compatible = "amlogic, aml_secos_memory";
			reg = <0x0 0x5300000 0x0 0x2000000>;
			no-map;
		};

                fb_reserved:linux,meson-fb {
                        compatible = "shared-dma-pool";
                        reusable;
                        size = <0x0 0x2400000>;
                        alignment = <0x0 0x400000>;
                        alloc-ranges = <0x0 0x7dc00000 0x0 0x2400000>;
                };

		linux,ion-dev {
			compatible = "shared-dma-pool";
			reusable;
			size = <0x0 0x8000000>;
			alignment = <0x0 0x400000>;
			linux,phandle = <0x1b>;
			phandle = <0x1b>;
		};

		linux,di_cma {
			compatible = "shared-dma-pool";
			reusable;
			size = <0x0 0x2800000>;
			alignment = <0x0 0x400000>;
			linux,phandle = <0x6f>;
			phandle = <0x6f>;
		};

		linux,ppmgr {
			compatible = "shared-dma-pool";
			size = <0x0 0x0>;
			linux,phandle = <0x6e>;
			phandle = <0x6e>;
		};

		linux,codec_mm_cma {
			compatible = "shared-dma-pool";
			reusable;
			size = <0x0 0x13400000>;
			alignment = <0x0 0x400000>;
			linux,contiguous-region;
			linux,phandle = <0x6c>;
			phandle = <0x6c>;
		};

		linux,codec_mm_reserved {
			compatible = "amlogic, codec-mm-reserved";
			size = <0x0 0x0>;
			alignment = <0x0 0x100000>;
			linux,phandle = <0x6d>;
			phandle = <0x6d>;
		};

		linux,vdin0_cma {
			compatible = "shared-dma-pool";
			reusable;
			size = <0x0 0x4000000>;
			alignment = <0x0 0x400000>;
			linux,phandle = <0x36>;
			phandle = <0x36>;
		};

		linux,vdin1_cma {
			compatible = "shared-dma-pool";
			reusable;
			size = <0x0 0x4000000>;
			alignment = <0x0 0x400000>;
			linux,phandle = <0x37>;
			phandle = <0x37>;
		};
	};

	gpioleds {
		compatible = "gpio-leds";
		status = "okay";

		net_green {
			label = "net_green";
			gpios = <0x15 0x4 0x0>;
			default-state = "on";
		};

		remote_led {
			label = "remote_led";
			gpios = <0x15 0xa 0x1>;
			default-state = "off";
			linux,default-trigger = "rc_feedback";
		};

		sys_led {
			label = "sys_led";
			gpios = <0x15 0xb 0x1>;
			default-state = "on";
			retain-state-suspended;
			linux,default-trigger = "cpu0";
		};
	};

	cvbsout {
		compatible = "amlogic, cvbsout-g12a";
		dev_name = "cvbsout";
		status = "okay";
		clocks = <0x2 0x55 0x2 0x4e 0x2 0x4f 0x2 0x57>;
		clock-names = "venci_top_gate", "venci_0_gate", "venci_1_gate", "vdac_clk_gate";
		clk_path = <0x0>;
		performance = <0x1bf0 0x9 0x1b56 0x333 0x1b12 0x8080 0x1b05 0xfd 0x1c59 0xf850 0xffff 0x0>;
		performance_sarft = <0x1bf0 0x9 0x1b56 0x333 0x1b12 0x0 0x1b05 0x9 0x1c59 0xfc48 0xffff 0x0>;
		performance_revB_telecom = <0x1bf0 0x9 0x1b56 0x546 0x1b12 0x8080 0x1b05 0x9 0x1c59 0xf850 0xffff 0x0>;
	};

	bt-dev {
		compatible = "amlogic, bt-dev";
		dev_name = "bt-dev";
		status = "okay";
		gpio_reset = <0x16 0x53 0x0>;
		gpio_hostwake = <0x16 0x55 0x0>;
	};

	wifi {
		compatible = "amlogic, aml_wifi";
		dev_name = "aml_wifi";
		status = "okay";
		interrupt_pin = <0x16 0x49 0x0>;
		irq_trigger_type = "GPIO_IRQ_LOW";
		power_on_pin = <0x16 0x48 0x0>;
		dhd_static_buf;
		pinctrl-names = "default";
		pinctrl-0 = <0x6a>;
		pwm_config = <0x6b>;
	};

	wifi_pwm_conf {
		linux,phandle = <0x6b>;
		phandle = <0x6b>;

		pwm_channel1_conf {
			pwms = <0x69 0x0 0x7558 0x0>;
			duty-cycle = <0x3aac>;
			times = <0xa>;
		};

		pwm_channel2_conf {
			pwms = <0x69 0x2 0x754e 0x0>;
			duty-cycle = <0x3aa7>;
			times = <0xc>;
		};
	};

	codec_mm {
		compatible = "amlogic, codec, mm";
		memory-region = <0x6c 0x6d>;
		dev_name = "codec_mm";
		status = "okay";
	};

	ppmgr {
		compatible = "amlogic, ppmgr";
		memory-region = <0x6e>;
		dev_name = "ppmgr";
		status = "okay";
	};

	deinterlace {
		compatible = "amlogic, deinterlace";
		status = "okay";
		flag_cma = <0x1>;
		memory-region = <0x6f>;
		interrupts = <0x0 0x2e 0x1 0x0 0x28 0x1>;
		interrupt-names = "pre_irq", "post_irq";
		clocks = <0x2 0x9b 0x2 0x9c>;
		clock-names = "vpu_clkb_tmp_composite", "vpu_clkb_composite";
		clock-range = <0x14e 0x29b>;
		buffer-size = <0x3e2c40>;
		post-wr-support = <0x1>;
		nr10bit-support = <0x1>;
		nrds-enable = <0x1>;
		pps-enable = <0x1>;
	};

	ionvideo {
		compatible = "amlogic, ionvideo";
		dev_name = "ionvideo";
		status = "okay";
	};

	dvb {
		compatible = "amlogic, dvb";
		dev_name = "dvb";
		status = "ok";
		ts2 = "parallel";
		ts2_control = <0x0>;
		ts2_invert = <0x0>;
	};

	unifykey {
		compatible = "amlogic, unifykey";
		status = "ok";
		unifykey-num = <0xf>;
		unifykey-index-0 = <0x70>;
		unifykey-index-1 = <0x71>;
		unifykey-index-2 = <0x72>;
		unifykey-index-3 = <0x73>;
		unifykey-index-4 = <0x74>;
		unifykey-index-5 = <0x75>;
		unifykey-index-6 = <0x76>;
		unifykey-index-7 = <0x77>;
		unifykey-index-8 = <0x78>;
		unifykey-index-9 = <0x79>;
		unifykey-index-10 = <0x7a>;
		unifykey-index-11 = <0x7b>;
		unifykey-index-12 = <0x7c>;
		unifykey-index-13 = <0x7d>;
		unifykey-index-14 = <0x7e>;

		key_0 {
			key-name = "usid";
			key-device = "normal";
			key-permit = "read", "write", "del";
			linux,phandle = <0x70>;
			phandle = <0x70>;
		};

		key_1 {
			key-name = "mac";
			key-device = "normal";
			key-permit = "read", "write", "del";
			linux,phandle = <0x71>;
			phandle = <0x71>;
		};

		key_2 {
			key-name = "hdcp";
			key-device = "secure";
			key-type = "sha1";
			key-permit = "read", "write", "del";
			linux,phandle = <0x72>;
			phandle = <0x72>;
		};

		key_3 {
			key-name = "secure_boot_set";
			key-device = "efuse";
			key-permit = "write";
			linux,phandle = <0x73>;
			phandle = <0x73>;
		};

		key_4 {
			key-name = "mac_bt";
			key-device = "normal";
			key-permit = "read", "write", "del";
			key-type = "mac";
			linux,phandle = <0x74>;
			phandle = <0x74>;
		};

		key_5 {
			key-name = "mac_wifi";
			key-device = "normal";
			key-permit = "read", "write", "del";
			key-type = "mac";
			linux,phandle = <0x75>;
			phandle = <0x75>;
		};

		key_6 {
			key-name = "hdcp2_tx";
			key-device = "normal";
			key-permit = "read", "write", "del";
			linux,phandle = <0x76>;
			phandle = <0x76>;
		};

		key_7 {
			key-name = "hdcp2_rx";
			key-device = "normal";
			key-permit = "read", "write", "del";
			linux,phandle = <0x77>;
			phandle = <0x77>;
		};

		key_8 {
			key-name = "widevinekeybox";
			key-device = "secure";
			key-permit = "read", "write", "del";
			linux,phandle = <0x78>;
			phandle = <0x78>;
		};

		key_9 {
			key-name = "deviceid";
			key-device = "normal";
			key-permit = "read", "write", "del";
			linux,phandle = <0x79>;
			phandle = <0x79>;
		};

		key_10 {
			key-name = "hdcp22_fw_private";
			key-device = "secure";
			key-permit = "read", "write", "del";
			linux,phandle = <0x7a>;
			phandle = <0x7a>;
		};

		key_11 {
			key-name = "PlayReadykeybox25";
			key-device = "secure";
			key-permit = "read", "write", "del";
			linux,phandle = <0x7b>;
			phandle = <0x7b>;
		};

		key_12 {
			key-name = "prpubkeybox";
			key-device = "secure";
			key-permit = "read", "write", "del";
			linux,phandle = <0x7c>;
			phandle = <0x7c>;
		};

		key_13 {
			key-name = "prprivkeybox";
			key-device = "secure";
			key-permit = "read", "write", "del";
			linux,phandle = <0x7d>;
			phandle = <0x7d>;
		};

		key_14 {
			key-name = "attestationkeybox";
			key-device = "secure";
			key-permit = "read", "write", "del";
			linux,phandle = <0x7e>;
			phandle = <0x7e>;
		};
	};

	efusekey {
		keynum = <0x4>;
		key0 = <0x7f>;
		key1 = <0x80>;
		key2 = <0x81>;
		key3 = <0x82>;
		linux,phandle = <0x58>;
		phandle = <0x58>;

		key_0 {
			keyname = "mac";
			offset = <0x0>;
			size = <0x6>;
			linux,phandle = <0x7f>;
			phandle = <0x7f>;
		};

		key_1 {
			keyname = "mac_bt";
			offset = <0x6>;
			size = <0x6>;
			linux,phandle = <0x80>;
			phandle = <0x80>;
		};

		key_2 {
			keyname = "mac_wifi";
			offset = <0xc>;
			size = <0x6>;
			linux,phandle = <0x81>;
			phandle = <0x81>;
		};

		key_3 {
			keyname = "usid";
			offset = <0x12>;
			size = <0x10>;
			linux,phandle = <0x82>;
			phandle = <0x82>;
		};
	};

	amlvecm {
		compatible = "amlogic, vecm";
		dev_name = "aml_vecm";
		status = "okay";
		gamma_en = <0x0>;
		wb_en = <0x0>;
		cm_en = <0x0>;
		tx_op_color_primary = <0x0>;
	};

	amdolby_vision {
		compatible = "amlogic, dolby_vision_g12a";
		dev_name = "aml_amdolby_vision_driver";
		status = "okay";
		tv_mode = <0x0>;
	};

	dummy {
		#sound-dai-cells = <0x0>;
		compatible = "amlogic, aml_dummy_codec";
		status = "okay";
		linux,phandle = <0x87>;
		phandle = <0x87>;
	};

	t9015 {
		#sound-dai-cells = <0x0>;
		compatible = "amlogic, aml_codec_T9015";
		reg = <0x0 0xff632000 0x0 0x2000>;
		is_auge_used = <0x1>;
		tdmout_index = <0x1>;
		status = "okay";
		linux,phandle = <0x84>;
		phandle = <0x84>;
	};

	eqdrc {
		eqdrc_module = <0x1>;
		lane_mask = <0x1>;
		channel_mask = <0x3>;
		linux,phandle = <0x85>;
		phandle = <0x85>;
	};

	auge_sound {
		compatible = "amlogic, g12a-sound-card";
		aml-audio-card,name = "AML-AUGESOUND";
		aml-audio-card,loopback = <0x83>;
		aml-audio-card,aux-devs = <0x84>;
		avout_mute-gpios = <0x15 0x2 0x0>;
		aml-audio-card,effect = <0x85>;

		aml-audio-card,dai-link@0 {
			format = "dsp_a";
			mclk-fs = <0x200>;
			suffix-name = "alsaPORT-pcm";

			cpu {
				sound-dai = <0x86>;
				dai-tdm-slot-tx-mask = <0x1 0x1 0x1 0x1 0x1 0x1 0x1 0x1>;
				dai-tdm-slot-rx-mask = <0x1 0x1 0x1 0x1 0x1 0x1 0x1 0x1>;
				dai-tdm-slot-num = <0x8>;
				dai-tdm-slot-width = <0x20>;
				system-clock-frequency = <0x1770000>;
			};

			codec {
				sound-dai = <0x87 0x87>;
			};
		};

		aml-audio-card,dai-link@1 {
			format = "i2s";
			mclk-fs = <0x100>;
			bitclock-master = <0x88>;
			frame-master = <0x88>;
			suffix-name = "alsaPORT-i2s";

			cpu {
				sound-dai = <0x88>;
				dai-tdm-slot-tx-mask = <0x1 0x1>;
				dai-tdm-slot-rx-mask = <0x1 0x1>;
				dai-tdm-slot-num = <0x2>;
				dai-tdm-slot-width = <0x20>;
				system-clock-frequency = <0xbb8000>;
			};

			codec {
				sound-dai = <0x87 0x87 0x84>;
			};
		};

		aml-audio-card,dai-link@2 {
			format = "i2s";
			mclk-fs = <0x100>;
			bitclock-master = <0x89>;
			frame-master = <0x89>;

			cpu {
				sound-dai = <0x89>;
				dai-tdm-slot-tx-mask = <0x1 0x1>;
				dai-tdm-slot-rx-mask = <0x1 0x1>;
				dai-tdm-slot-num = <0x2>;
				dai-tdm-slot-width = <0x20>;
				system-clock-frequency = <0xbb8000>;
			};

			codec {
				sound-dai = <0x87 0x87>;
			};
		};

		aml-audio-card,dai-link@3 {
			mclk-fs = <0x40>;
			suffix-name = "alsaPORT-pdm";

			cpu {
				sound-dai = <0x8a>;
			};

			codec {
				sound-dai = <0x87>;
			};
		};

		aml-audio-card,dai-link@4 {
			mclk-fs = <0x80>;
			continuous-clock;
			suffix-name = "alsaPORT-spdifb2hdmi";

			cpu {
				sound-dai = <0x8b>;
				system-clock-frequency = <0x5dc000>;
			};

			codec {
				sound-dai = <0x87>;
			};
		};

		aml-audio-card,dai-link@5 {
			mclk-fs = <0x80>;
			continuous-clock;
			suffix-name = "alsaPORT-spdif";

			cpu {
				sound-dai = <0x8c>;
				system-clock-frequency = <0x5dc000>;
			};

			codec {
				sound-dai = <0x87>;
			};
		};
	};

	locker {
		compatible = "amlogic, audiolocker";
		clocks = <0x1c 0x22 0x1c 0x23 0x1c 0x1a 0x1c 0x1b 0x2 0xd 0x2 0xe>;
		clock-names = "lock_out", "lock_in", "out_src", "in_src", "out_calc", "in_ref";
		interrupts = <0x0 0x1 0x1>;
		interrupt-names = "irq";
		frequency = <0x2ebae40>;
		dividor = <0x31>;
		status = "okay";
	};

	cpu_opp_table0 {
		compatible = "operating-points-v2";
		opp-shared;
		linux,phandle = <0xd>;
		phandle = <0xd>;

		opp00 {
			opp-hz = <0x0 0x5f5e100>;
			opp-microvolt = <0xb2778>;
		};

		opp01 {
			opp-hz = <0x0 0xee6b280>;
			opp-microvolt = <0xb2778>;
		};

		opp02 {
			opp-hz = <0x0 0x1dcd6500>;
			opp-microvolt = <0xb2778>;
		};

		opp03 {
			opp-hz = <0x0 0x27c19cc0>;
			opp-microvolt = <0xb2778>;
		};

		opp04 {
			opp-hz = <0x0 0x3b9aca00>;
			opp-microvolt = <0xb2778>;
		};

		opp05 {
			opp-hz = <0x0 0x47868c00>;
			opp-microvolt = <0xb9ca8>;
		};

		opp06 {
			opp-hz = <0x0 0x5353c980>;
			opp-microvolt = <0xc11d8>;
		};

		opp07 {
			opp-hz = <0x0 0x5a1f4a00>;
			opp-microvolt = <0xcae18>;
		};

		opp08 {
			opp-hz = <0x0 0x5fd82200>;
			opp-microvolt = <0xd4a58>;
		};

		opp09 {
			opp-hz = <0x0 0x6590fa00>;
			opp-microvolt = <0xe0da8>;
		};

		opp10 {
			opp-hz = <0x0 0x71b9c500>;
			opp-microvolt = <0xf6d38>;
		};
	};

	cpufreq-meson {
		compatible = "amlogic, cpufreq-meson";
		pinctrl-names = "default";
		pinctrl-0 = <0x8d>;
		status = "okay";
	};

	aml_vfd {
		compatible = "amlogic,aml_vfd";
		dev_name = "aml_vfd";
		stb_gpio = <0x15 0x7 0x0>;
		clk_gpio = <0x15 0x6 0x0>;
		data_gpio = <0x15 0x9 0x0>;
		status = "okay";
	};
};
